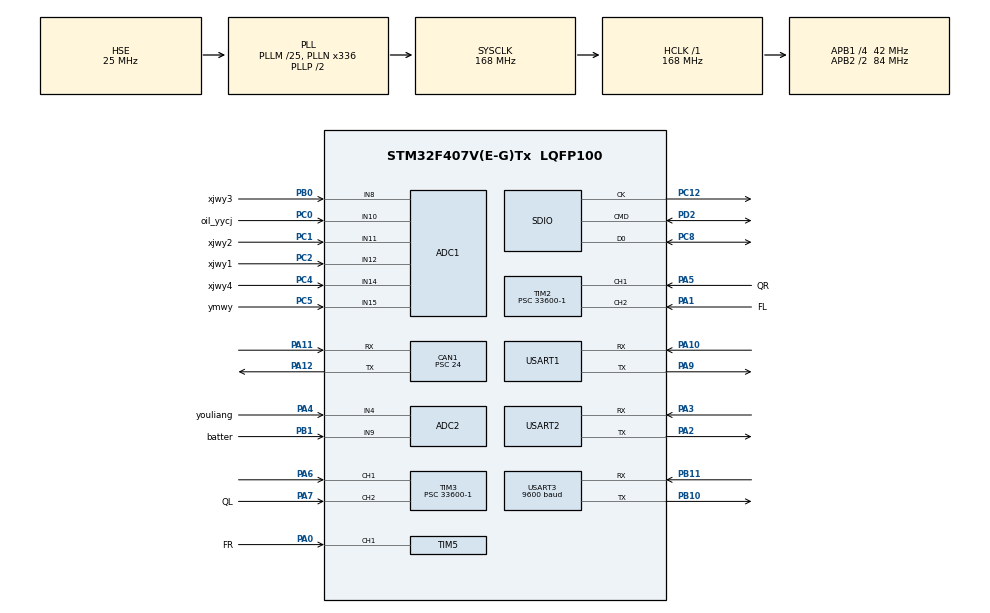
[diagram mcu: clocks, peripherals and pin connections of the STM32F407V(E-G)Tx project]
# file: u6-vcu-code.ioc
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ADC1.Channel-0\#ChannelRegularConversion=ADC_CHANNEL_12
ADC1.Channel-1\#ChannelRegularConversion=ADC_CHANNEL_11
ADC1.Channel-2\#ChannelRegularConversion=ADC_CHANNEL_8
ADC1.Channel-3\#ChannelRegularConversion=ADC_CHANNEL_14
ADC1.Channel-4\#ChannelRegularConversion=ADC_CHANNEL_10
ADC1.Channel-5\#ChannelRegularConversion=ADC_CHANNEL_15
ADC1.ContinuousConvMode=ENABLE
ADC1.DMAContinuousRequests=ENABLE
ADC1.DiscontinuousConvMode=DISABLE
ADC1.EOCSelection=ADC_EOC_SINGLE_CONV
ADC1.InjNumberOfConversion=0
ADC1.NbrOfConversion=6
ADC1.NbrOfConversionFlag=1
ADC1.Rank-0\#ChannelRegularConversion=1
ADC1.Rank-1\#ChannelRegularConversion=2
ADC1.Rank-2\#ChannelRegularConversion=3
ADC1.Rank-3\#ChannelRegularConversion=4
ADC1.Rank-4\#ChannelRegularConversion=5
ADC1.Rank-5\#ChannelRegularConversion=6
ADC1.SamplingTime-0\#ChannelRegularConversion=ADC_SAMPLETIME_480CYCLES
ADC1.SamplingTime-1\#ChannelRegularConversion=ADC_SAMPLETIME_480CYCLES
ADC1.SamplingTime-2\#ChannelRegularConversion=ADC_SAMPLETIME_480CYCLES
ADC1.SamplingTime-3\#ChannelRegularConversion=ADC_SAMPLETIME_480CYCLES
ADC1.SamplingTime-4\#ChannelRegularConversion=ADC_SAMPLETIME_480CYCLES
ADC1.SamplingTime-5\#ChannelRegularConversion=ADC_SAMPLETIME_480CYCLES
ADC1.ScanConvMode=ENABLE
ADC1.master=1
ADC2.Channel-0\#ChannelRegularConversion=ADC_CHANNEL_4
ADC2.Channel-1\#ChannelRegularConversion=ADC_CHANNEL_9
ADC2.ContinuousConvMode=ENABLE
ADC2.DMAContinuousRequests=ENABLE
ADC2.NbrOfConversion=2
ADC2.NbrOfConversionFlag=1
ADC2.Rank-0\#ChannelRegularConversion=1
ADC2.Rank-1\#ChannelRegularConversion=2
ADC2.SamplingTime-0\#ChannelRegularConversion=ADC_SAMPLETIME_480CYCLES
ADC2.SamplingTime-1\#ChannelRegularConversion=ADC_SAMPLETIME_480CYCLES
ADC2.ScanConvMode=ENABLE
CAN1.BS1=CAN_BS1_3TQ
CAN1.BS2=CAN_BS2_3TQ
CAN1.CalculateBaudRate=250000
CAN1.CalculateTimeBit=4000
CAN1.CalculateTimeQuantum=571.4285714285714
CAN1.Mode=CAN_MODE_NORMAL
CAN1.NART=DISABLE
CAN1.Prescaler=24
CAN1.TXFP=ENABLE
Dma.ADC1.5.Direction=DMA_PERIPH_TO_MEMORY
Dma.ADC1.5.FIFOMode=DMA_FIFOMODE_DISABLE
Dma.ADC1.5.Instance=DMA2_Stream0
Dma.ADC1.5.MemDataAlignment=DMA_MDATAALIGN_WORD
Dma.ADC1.5.MemInc=DMA_MINC_ENABLE
Dma.ADC1.5.Mode=DMA_CIRCULAR
Dma.ADC1.5.PeriphDataAlignment=DMA_PDATAALIGN_WORD
Dma.ADC1.5.PeriphInc=DMA_PINC_DISABLE
Dma.ADC1.5.Priority=DMA_PRIORITY_MEDIUM
Dma.ADC2.4.Direction=DMA_PERIPH_TO_MEMORY
Dma.ADC2.4.FIFOMode=DMA_FIFOMODE_ENABLE
Dma.ADC2.4.FIFOThreshold=DMA_FIFO_THRESHOLD_FULL
Dma.ADC2.4.Instance=DMA2_Stream2
Dma.ADC2.4.MemBurst=DMA_MBURST_SINGLE
Dma.ADC2.4.MemDataAlignment=DMA_MDATAALIGN_WORD
Dma.ADC2.4.MemInc=DMA_MINC_ENABLE
Dma.ADC2.4.Mode=DMA_CIRCULAR
Dma.ADC2.4.PeriphBurst=DMA_PBURST_SINGLE
Dma.ADC2.4.PeriphDataAlignment=DMA_PDATAALIGN_WORD
Dma.ADC2.4.PeriphInc=DMA_PINC_DISABLE
Dma.ADC2.4.Priority=DMA_PRIORITY_MEDIUM
Dma.Request0=SDIO_RX
Dma.Request1=SDIO_TX
Dma.Request2=USART1_TX
Dma.Request3=USART2_RX
Dma.Request4=ADC2
Dma.Request5=ADC1
Dma.SDIO_RX.0.Direction=DMA_PERIPH_TO_MEMORY
Dma.SDIO_RX.0.FIFOMode=DMA_FIFOMODE_ENABLE
Dma.SDIO_RX.0.FIFOThreshold=DMA_FIFO_THRESHOLD_FULL
Dma.SDIO_RX.0.Instance=DMA2_Stream3
Dma.SDIO_RX.0.MemBurst=DMA_MBURST_INC4
Dma.SDIO_RX.0.MemDataAlignment=DMA_MDATAALIGN_WORD
Dma.SDIO_RX.0.MemInc=DMA_MINC_ENABLE
Dma.SDIO_RX.0.Mode=DMA_PFCTRL
Dma.SDIO_RX.0.PeriphBurst=DMA_PBURST_INC4
Dma.SDIO_RX.0.PeriphDataAlignment=DMA_PDATAALIGN_WORD
Dma.SDIO_RX.0.PeriphInc=DMA_PINC_DISABLE
Dma.SDIO_RX.0.Priority=DMA_PRIORITY_MEDIUM
Dma.SDIO_TX.1.Direction=DMA_MEMORY_TO_PERIPH
Dma.SDIO_TX.1.FIFOMode=DMA_FIFOMODE_ENABLE
Dma.SDIO_TX.1.FIFOThreshold=DMA_FIFO_THRESHOLD_FULL
Dma.SDIO_TX.1.Instance=DMA2_Stream6
Dma.SDIO_TX.1.MemBurst=DMA_MBURST_INC4
Dma.SDIO_TX.1.MemDataAlignment=DMA_MDATAALIGN_WORD
Dma.SDIO_TX.1.MemInc=DMA_MINC_ENABLE
Dma.SDIO_TX.1.Mode=DMA_PFCTRL
Dma.SDIO_TX.1.PeriphBurst=DMA_PBURST_INC4
Dma.SDIO_TX.1.PeriphDataAlignment=DMA_PDATAALIGN_WORD
Dma.SDIO_TX.1.PeriphInc=DMA_PINC_DISABLE
Dma.SDIO_TX.1.Priority=DMA_PRIORITY_MEDIUM
Dma.USART1_TX.2.Direction=DMA_MEMORY_TO_PERIPH
Dma.USART1_TX.2.FIFOMode=DMA_FIFOMODE_DISABLE
Dma.USART1_TX.2.Instance=DMA2_Stream7
Dma.USART1_TX.2.MemDataAlignment=DMA_MDATAALIGN_BYTE
Dma.USART1_TX.2.MemInc=DMA_MINC_ENABLE
Dma.USART1_TX.2.Mode=DMA_NORMAL
Dma.USART1_TX.2.PeriphDataAlignment=DMA_PDATAALIGN_BYTE
Dma.USART1_TX.2.PeriphInc=DMA_PINC_DISABLE
Dma.USART1_TX.2.Priority=DMA_PRIORITY_LOW
Dma.USART2_RX.3.Direction=DMA_PERIPH_TO_MEMORY
Dma.USART2_RX.3.FIFOMode=DMA_FIFOMODE_DISABLE
Dma.USART2_RX.3.Instance=DMA1_Stream5
Dma.USART2_RX.3.MemDataAlignment=DMA_MDATAALIGN_BYTE
Dma.USART2_RX.3.MemInc=DMA_MINC_ENABLE
Dma.USART2_RX.3.Mode=DMA_NORMAL
Dma.USART2_RX.3.PeriphDataAlignment=DMA_PDATAALIGN_BYTE
Dma.USART2_RX.3.PeriphInc=DMA_PINC_DISABLE
Dma.USART2_RX.3.Priority=DMA_PRIORITY_VERY_HIGH
FATFS._CODE_PAGE=936
FATFS._MAX_SS=4096
FATFS._MIN_SS=512
FATFS._USE_LFN=2
FREERTOS.BinarySemaphores01=CanBinarySem,Static,CanBinarySemControlBlock;Onenet_tx_BinarySem,Static,Onenet_tx_BinarySemControlBlock;TyreBinarySem,Static,TypeBinarySemControlBlock
FREERTOS.Events01=Vcu_Event1,Static,Vcu_Event1ControlBlock;Can_Event,Static,Can_EventControlBlock;MT_Event,Static,MT_EventControlBlock;SD_Event,Static,SD_EventControlBlock
FREERTOS.Mutexes01=MqttMutex,Static,MqttMutexControlBlock
FREERTOS.Queues01=UsartQueue,4,64,1,Dynamic,NULL,NULL
FREERTOS.Tasks01=Wit_dat_Task,9,512,Wit_Dat_Handle,Default,NULL,Dynamic,NULL,NULL;Can_Rx_Task,10,128,Can_Rx_Handle,Default,NULL,Dynamic,NULL,NULL;RB_Read_Task,12,512,RingBuffer_Read_Handle,Default,NULL,Dynamic,NULL,NULL;OilDisplay_Task,13,512,OilDisplayment_Handle,Default,NULL,Dynamic,NULL,NULL;DTU_Init_Task,43,128,DTU_Init_Handle,Default,NULL,Dynamic,NULL,NULL;Signal_4G_Task,8,256,Signal_4G_Handle,Default,NULL,Dynamic,NULL,NULL;GPS_Init_Task,42,128,GPS_Init_Handle,Default,NULL,Dynamic,NULL,NULL;GPS_Get_Task,11,256,GPS_Get_Handle,Default,NULL,Dynamic,NULL,NULL;IWDG_Task,40,128,IWDG_Handle,Default,NULL,Dynamic,NULL,NULL;Otheradc_task,8,256,Oadc_Handle,Default,NULL,Dynamic,NULL,NULL;CantxTask,32,256,Cantx_Handle,Default,NULL,Static,CantxTaskBuffer,CantxTaskControlBlock;TyreSpeedTask,15,256,TyreSpeed_Handle,Default,NULL,Dynamic,NULL,NULL;SD_Init_task,41,128,SD_Init_Handle,Default,NULL,Dynamic,NULL,NULL;RTCTask,8,128,RTC_Handle,Default,NULL,Static,RTCTaskBuffer,RTCTaskControlBlock;CanrxTask,8,128,Canrx_Handle,Default,NULL,Dynamic,NULL,NULL
FREERTOS.configENABLE_FPU=1
FREERTOS.configLIBRARY_MAX_SYSCALL_INTERRUPT_PRIORITY=2
IWDG.Prescaler=IWDG_PRESCALER_32
IWDG.Reload=1000
Mcu.Family=STM32F4
Mcu.Name=STM32F407V(E-G)Tx
Mcu.Package=LQFP100
NVIC.ADC_IRQn=true\:2\:0\:false\:false\:true\:true\:true\:true\:true
NVIC.CAN1_RX0_IRQn=true\:2\:0\:false\:false\:true\:true\:true\:true\:true
NVIC.CAN1_TX_IRQn=true\:2\:0\:false\:false\:true\:true\:true\:true\:true
NVIC.DMA1_Stream5_IRQn=true\:2\:0\:false\:false\:true\:true\:false\:true\:true
NVIC.DMA2_Stream0_IRQn=true\:2\:0\:false\:false\:true\:true\:false\:true\:true
NVIC.DMA2_Stream2_IRQn=true\:2\:0\:false\:false\:true\:true\:false\:true\:true
NVIC.DMA2_Stream3_IRQn=true\:10\:0\:true\:false\:true\:true\:false\:true\:true
NVIC.DMA2_Stream6_IRQn=true\:10\:0\:true\:false\:true\:true\:false\:true\:true
NVIC.DMA2_Stream7_IRQn=true\:7\:0\:true\:false\:true\:true\:false\:true\:true
NVIC.FPU_IRQn=true\:2\:0\:true\:false\:true\:true\:true\:false\:true
NVIC.PriorityGroup=NVIC_PRIORITYGROUP_4
NVIC.SDIO_IRQn=true\:2\:0\:true\:false\:true\:true\:true\:true\:true
NVIC.TIM1_UP_TIM10_IRQn=true\:15\:0\:false\:false\:true\:false\:false\:true\:true
NVIC.TIM2_IRQn=true\:2\:0\:false\:false\:true\:true\:true\:true\:true
NVIC.TIM3_IRQn=true\:2\:0\:false\:false\:true\:true\:true\:true\:true
NVIC.TIM5_IRQn=true\:2\:0\:false\:false\:true\:true\:true\:true\:true
NVIC.TIM7_IRQn=true\:2\:0\:false\:false\:true\:true\:true\:true\:true
NVIC.TIM8_TRG_COM_TIM14_IRQn=true\:2\:0\:false\:false\:true\:true\:true\:true\:true
NVIC.TIM8_UP_TIM13_IRQn=true\:2\:0\:false\:false\:true\:true\:true\:true\:true
NVIC.TimeBase=TIM1_UP_TIM10_IRQn
NVIC.TimeBaseIP=TIM1
NVIC.USART2_IRQn=true\:5\:0\:true\:false\:true\:true\:true\:true\:true
NVIC.USART3_IRQn=true\:5\:0\:true\:false\:true\:true\:true\:true\:true
PA0-WKUP.GPIO_Label=FR
PA0-WKUP.Signal=S_TIM5_CH1
PA1.GPIO_Label=FL
PA1.Signal=S_TIM2_CH2
PA10.Mode=Asynchronous
PA10.Signal=USART1_RX
PA11.Mode=CAN_Activate
PA11.Signal=CAN1_RX
PA12.Mode=CAN_Activate
PA12.Signal=CAN1_TX
PA13.Mode=Serial_Wire
PA13.Signal=SYS_JTMS-SWDIO
PA14.Mode=Serial_Wire
PA14.Signal=SYS_JTCK-SWCLK
PA2.Mode=Asynchronous
PA2.Signal=USART2_TX
PA3.Mode=Asynchronous
PA3.Signal=USART2_RX
PA4.GPIO_Label=youliang
PA4.Signal=ADCx_IN4
PA5.GPIO_Label=QR
PA5.Signal=S_TIM2_CH1_ETR
PA6.Signal=S_TIM3_CH1
PA7.GPIO_Label=QL
PA7.Signal=S_TIM3_CH2
PA9.Mode=Asynchronous
PA9.Signal=USART1_TX
PB0.GPIO_Label=xjwy3
PB0.Signal=ADCx_IN8
PB1.GPIO_Label=batter
PB1.Signal=ADCx_IN9
PB10.Mode=Asynchronous
PB10.Signal=USART3_TX
PB11.Mode=Asynchronous
PB11.Signal=USART3_RX
PC0.GPIO_Label=oil_yycj
PC0.Signal=ADCx_IN10
PC1.GPIO_Label=xjwy2
PC1.Signal=ADCx_IN11
PC12.GPIO_PuPd=GPIO_PULLUP
PC12.Mode=SD_1_bit
PC12.Signal=SDIO_CK
PC2.GPIO_Label=xjwy1
PC2.Signal=ADCx_IN12
PC4.GPIO_Label=xjwy4
PC4.Signal=ADCx_IN14
PC5.GPIO_Label=ymwy
PC5.Signal=ADCx_IN15
PC8.GPIO_PuPd=GPIO_PULLUP
PC8.Mode=SD_1_bit
PC8.Signal=SDIO_D0
PD2.GPIO_PuPd=GPIO_PULLUP
PD2.Mode=SD_1_bit
PD2.Signal=SDIO_CMD
PH0-OSC_IN.Mode=HSE-External-Oscillator
PH0-OSC_IN.Signal=RCC_OSC_IN
PH1-OSC_OUT.Mode=HSE-External-Oscillator
PH1-OSC_OUT.Signal=RCC_OSC_OUT
ProjectManager.HeapSize=0x1000
ProjectManager.StackSize=0x1000
ProjectManager.TargetToolchain=MDK-ARM V5
RCC.48MHZClocksFreq_Value=48000000
RCC.AHBFreq_Value=168000000
RCC.APB1CLKDivider=RCC_HCLK_DIV4
RCC.APB1Freq_Value=42000000
RCC.APB1TimFreq_Value=84000000
RCC.APB2CLKDivider=RCC_HCLK_DIV2
RCC.APB2Freq_Value=84000000
RCC.APB2TimFreq_Value=168000000
RCC.CortexFreq_Value=168000000
RCC.HCLKFreq_Value=168000000
RCC.HSE_VALUE=25000000
RCC.HSI_VALUE=16000000
RCC.MCO1OutPutEnable-ClockTree=true
RCC.PLLI2SN=50
RCC.PLLM=25
RCC.PLLN=336
RCC.PLLQ=7
RCC.PLLSourceVirtual=RCC_PLLSOURCE_HSE
RCC.RCC_RTC_Clock_Source_FROM_HSE=RCC_RTCCLKSOURCE_HSE_DIV25
RCC.SYSCLKFreq_VALUE=168000000
RCC.SYSCLKSource=RCC_SYSCLKSOURCE_PLLCLK
RCC.USBHSEnable-ClockTree=true
RCC.VCOOutputFreq_Value=336000000
RTC.AsynchPrediv=4
RTC.Date=13
RTC.Hours=19
RTC.Month=RTC_MONTH_APRIL
RTC.WeekDay=RTC_WEEKDAY_SATURDAY
RTC.Year=24
SDIO.ClockDiv=0
SDIO.HardwareFlowControl=SDIO_HARDWARE_FLOW_CONTROL_DISABLE
SH.ADCx_IN10.0=ADC1_IN10,IN10
SH.ADCx_IN11.0=ADC1_IN11,IN11
SH.ADCx_IN12.0=ADC1_IN12,IN12
SH.ADCx_IN14.0=ADC1_IN14,IN14
SH.ADCx_IN15.0=ADC1_IN15,IN15
SH.ADCx_IN4.0=ADC2_IN4,IN4
SH.ADCx_IN8.0=ADC1_IN8,IN8
SH.ADCx_IN9.0=ADC2_IN9,IN9
SH.S_TIM2_CH1_ETR.0=TIM2_CH1,Input_Capture1_from_TI1
SH.S_TIM2_CH2.0=TIM2_CH2,Input_Capture2_from_TI2
SH.S_TIM3_CH1.0=TIM3_CH1,Input_Capture1_from_TI1
SH.S_TIM3_CH2.0=TIM3_CH2,Input_Capture2_from_TI2
SH.S_TIM5_CH1.0=TIM5_CH1,Input_Capture1_from_TI1
TIM13.Period=30000
TIM13.Prescaler=33600-1
TIM14.AutoReloadPreload=TIM_AUTORELOAD_PRELOAD_DISABLE
TIM14.Period=5-1
TIM14.Prescaler=33600-1
TIM2.AutoReloadPreload=TIM_AUTORELOAD_PRELOAD_ENABLE
TIM2.Channel-Input_Capture1_from_TI1=TIM_CHANNEL_1
TIM2.Channel-Input_Capture2_from_TI2=TIM_CHANNEL_2
TIM2.Prescaler=33600-1
TIM3.Channel-Input_Capture1_from_TI1=TIM_CHANNEL_1
TIM3.Channel-Input_Capture2_from_TI2=TIM_CHANNEL_2
TIM3.Period=50000
TIM3.Prescaler=33600-1
TIM5.Channel-Input_Capture1_from_TI1=TIM_CHANNEL_1
TIM5.Prescaler=33600-1
TIM7.Period=10-1
TIM7.Prescaler=16800-1
USART1.VirtualMode=VM_ASYNC
USART2.VirtualMode=VM_ASYNC
USART3.BaudRate=9600
USART3.VirtualMode=VM_ASYNC
VP_FATFS_VS_SDIO.Mode=SDIO
VP_FREERTOS_VS_CMSIS_V2.Mode=CMSIS_V2
VP_IWDG_VS_IWDG.Mode=IWDG_Activate
VP_RTC_VS_RTC_Activate.Mode=RTC_Enabled
VP_RTC_VS_RTC_Calendar.Mode=RTC_Calendar
VP_SYS_VS_tim1.Mode=TIM1
VP_TIM13_VS_ClockSourceINT.Mode=Enable_Timer
VP_TIM14_VS_ClockSourceINT.Mode=Enable_Timer
VP_TIM2_VS_ClockSourceINT.Mode=Internal
VP_TIM3_VS_ClockSourceINT.Mode=Internal
VP_TIM5_VS_ClockSourceINT.Mode=Internal
VP_TIM7_VS_ClockSourceINT.Mode=Enable_Timer
board=custom

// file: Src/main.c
/* USER CODE BEGIN Header */
/**
  ******************************************************************************
  * @file           : main.c
  * @brief          : Main program body
  ******************************************************************************
  * @attention
  *
  * Copyright (c) 2023 STMicroelectronics.
  * All rights reserved.
  *
  * This software is licensed under terms that can be found in the LICENSE file
  * in the root directory of this software component.
  * If no LICENSE file comes with this software, it is provided AS-IS.
  *
  ******************************************************************************
  */
/* USER CODE END Header */
#include "main.h"
#include "cmsis_os.h"
#include "adc.h"
#include "can.h"
#include "dma.h"
#include "fatfs.h"
#include "iwdg.h"
#include "rtc.h"
#include "sdio.h"
#include "tim.h"
#include "usart.h"
#include "gpio.h"

/* USER CODE BEGIN Includes */
#include "wit_c_sdk.h"
#include "atk_m750.h"
#include "RingBuffer.h"
#include "string.h"
#include "gps.h"
#include "mtspeed.h"
/* USER CODE END Includes */

/* USER CODE BEGIN PTD */
/*******************************************
	*文件名 ：  U6_VCU
	*作   者：  罗成
	*修改时间： 2024.4.18
	*版   本：  v5.1.6
	*声   明：  本程序归飞翼车队所有，未经车队队长及指导老师允许，不能对外传播
	*提   示：  本程序采用Git进行版本管理，可通过git退回以前版本，但在选择时请选择
							最高版本（随版本递增，功能逐步递增）
							github仓库：https://github.com/TheorangeMr/U6xxxx.git
*******************************************/
/* USER CODE END PTD */

/* USER CODE BEGIN PV */

extern uint8_t Oil_base_dat;
extern mt_rotate mtspeed1;
extern mt_rotate mtspeed2;
extern mt_rotate mtspeed3;
extern mt_rotate mtspeed4;
extern mt_rotate mtspeed5;
extern __IO uint16_t USART3_RX_STA;

uint8_t cantx_dat[8] = {0};
uint8_t time3_over1 = 0,time3_over2 = 0;

/* USER CODE END PV */

void SystemClock_Config(void);
void MX_FREERTOS_Init(void);

/* USER CODE BEGIN 0 */

/*
	函数名：Wit_Can_Send_Msg()
	功  能：CAN发送帧函数
  参  数：u8 ucStdId：扩展标识符, u8* msg：数据指针, u8 len：数据长度
  返回值：PASSED:传输成功，FAILED:失败
*/

void Wit_Can_Send_Msg(uint8_t ucStdId, uint8_t* msg, uint32_t len)
{
	uint16_t i=0;uint32_t can_tx_mailbox = 0;
	uint8_t canovertime = 0;
	CAN_TxHeaderTypeDef TxMessage;
	TxMessage.StdId=ucStdId;
	TxMessage.ExtId=0;
	TxMessage.IDE=CAN_ID_STD;
	TxMessage.RTR=CAN_RTR_DATA;
	TxMessage.DLC=len;
	TxMessage.TransmitGlobalTime=DISABLE;
	for(i=0;i<len;i++)
	cantx_dat[i]=msg[i];
	while(HAL_CAN_GetTxMailboxesFreeLevel(&hcan1) < 1){
		if(canovertime++ >= 5){
			break;
		}else{
			osDelay(1);
		}
	}
	if(HAL_CAN_AddTxMessage(&hcan1,&TxMessage,cantx_dat,&can_tx_mailbox) != HAL_OK)
	{
		printf ("data sending failure！\r\n");
	}
}

/* USER CODE END 0 */

int main(void)
{

  /* MCU Configuration--------------------------------------------------------*/

  /* Reset of all peripherals, Initializes the Flash interface and the Systick. */
  HAL_Init();

  /* Configure the system clock */
  SystemClock_Config();

  /* Initialize all configured peripherals */
  MX_GPIO_Init();
  MX_DMA_Init();
  MX_CAN1_Init();
  MX_SDIO_SD_Init();
  MX_FATFS_Init();
  MX_USART1_UART_Init();
  MX_USART2_UART_Init();
  MX_USART3_UART_Init();
  MX_ADC1_Init();
  MX_TIM2_Init();
  MX_TIM14_Init();
  MX_IWDG_Init();
  MX_ADC2_Init();
  MX_TIM3_Init();
  MX_TIM5_Init();
  MX_TIM7_Init();
  MX_TIM13_Init();
  MX_RTC_Init();
  /* USER CODE BEGIN 2 */

	//nine-axis dvice initialize
	WitInit(WIT_PROTOCOL_CAN, 0x50);
	WitRegisterCallBack(SensorDataUpdata);
	WitCanWriteRegister(Wit_Can_Send_Msg);
	WitDelayMsRegister(Wit_Delayms);

	HAL_GPIO_WritePin(GPIOB,GPIO_PIN_3,GPIO_PIN_RESET);
	HAL_GPIO_WritePin(GPIOA,GPIO_PIN_15,GPIO_PIN_RESET);

	BSP_SD_Init();
  printf("外设初始化\r\n");
  /* USER CODE END 2 */

  /* Init scheduler */
  osKernelInitialize();  /* Call init function for freertos objects (in freertos.c) */
  MX_FREERTOS_Init();

  /* Start scheduler */
  osKernelStart();
  /* We should never get here as control is now taken by the scheduler */
  /* Infinite loop */
  while (1)
  {

  }
}

void SystemClock_Config(void)
{
  RCC_OscInitTypeDef RCC_OscInitStruct = {0};
  RCC_ClkInitTypeDef RCC_ClkInitStruct = {0};

  /** Configure the main internal regulator output voltage
  */
  __HAL_RCC_PWR_CLK_ENABLE();
  __HAL_PWR_VOLTAGESCALING_CONFIG(PWR_REGULATOR_VOLTAGE_SCALE1);

  /** Initializes the RCC Oscillators according to the specified parameters
  * in the RCC_OscInitTypeDef structure.
  */
  RCC_OscInitStruct.OscillatorType = RCC_OSCILLATORTYPE_LSI|RCC_OSCILLATORTYPE_HSE;
  RCC_OscInitStruct.HSEState = RCC_HSE_ON;
  RCC_OscInitStruct.LSIState = RCC_LSI_ON;
  RCC_OscInitStruct.PLL.PLLState = RCC_PLL_ON;
  RCC_OscInitStruct.PLL.PLLSource = RCC_PLLSOURCE_HSE;
  RCC_OscInitStruct.PLL.PLLM = 25;
  RCC_OscInitStruct.PLL.PLLN = 336;
  RCC_OscInitStruct.PLL.PLLP = RCC_PLLP_DIV2;
  RCC_OscInitStruct.PLL.PLLQ = 7;
  if (HAL_RCC_OscConfig(&RCC_OscInitStruct) != HAL_OK)
  {
    Error_Handler();
  }

  /** Initializes the CPU, AHB and APB buses clocks
  */
  RCC_ClkInitStruct.ClockType = RCC_CLOCKTYPE_HCLK|RCC_CLOCKTYPE_SYSCLK
                              |RCC_CLOCKTYPE_PCLK1|RCC_CLOCKTYPE_PCLK2;
  RCC_ClkInitStruct.SYSCLKSource = RCC_SYSCLKSOURCE_PLLCLK;
  RCC_ClkInitStruct.AHBCLKDivider = RCC_SYSCLK_DIV1;
  RCC_ClkInitStruct.APB1CLKDivider = RCC_HCLK_DIV4;
  RCC_ClkInitStruct.APB2CLKDivider = RCC_HCLK_DIV2;

  if (HAL_RCC_ClockConfig(&RCC_ClkInitStruct, FLASH_LATENCY_5) != HAL_OK)
  {
    Error_Handler();
  }
}

void HAL_TIM_PeriodElapsedCallback(TIM_HandleTypeDef *htim)
{
  /* USER CODE BEGIN Callback 0 */
	#define mt_cycle   300                     //mt算法采样周期
	#define reset_cycle   800                  //当不采样时的清零周期

	static uint8_t tim14_count = 0;
  /* USER CODE END Callback 0 */
  if (htim->Instance == TIM1) {
    HAL_IncTick();
  }
  /* USER CODE BEGIN Callback 1 */

  if (htim->Instance == TIM14) {
		if(mtspeed1.timecountflag){
			mtspeed1.timecount++;
			if(mtspeed1.timecount >= mt_cycle){
				mtspeed1.timecount = 0;
				mtspeed1.timecountflag = 0;
				mtspeed1.Endup_Flag = 1;                                           //规定周期采样结束标志
			}
		}else{
			mtspeed1.speed_zero++;
			if(mtspeed1.speed_zero >= reset_cycle){
				mtspeed1.Rotate_Speed = 0;
			}
		}
		if(mtspeed2.timecountflag){
			mtspeed2.timecount++;
			if(mtspeed2.timecount >= mt_cycle){
				mtspeed2.timecountflag = 0;
				mtspeed2.timecount = 0;
				mtspeed2.Endup_Flag = 1;                                           //规定周期采样结束标志
			}
		}else{
			mtspeed2.speed_zero++;
			if(mtspeed2.speed_zero >= reset_cycle){
				mtspeed2.Rotate_Speed = 0;
			}
		}
		if(mtspeed3.timecountflag){
			mtspeed3.timecount++;
			if(mtspeed3.timecount >= mt_cycle){
				mtspeed3.timecountflag = 0;
				mtspeed3.timecount = 0;
				mtspeed3.Endup_Flag = 1;                                           //规定周期采样结束标志
			}
		}else{
			mtspeed3.speed_zero++;
			if(mtspeed3.speed_zero >= reset_cycle){
				mtspeed3.Rotate_Speed = 0;
			}
		}
		if(mtspeed4.timecountflag){
			mtspeed4.timecount++;
			if(mtspeed4.timecount >= mt_cycle){
				mtspeed4.timecountflag = 0;
				mtspeed4.timecount = 0;
				mtspeed4.Endup_Flag = 1;                                           //规定周期采样结束标志
			}
		}else{
			mtspeed4.speed_zero++;
			if(mtspeed4.speed_zero >= reset_cycle){
				mtspeed4.Rotate_Speed = 0;
			}
		}
		if(mtspeed5.timecountflag){
			mtspeed5.timecount++;
			if(mtspeed5.timecount >= mt_cycle){
				mtspeed5.timecountflag = 0;
				mtspeed5.timecount = 0;
				mtspeed5.Endup_Flag = 1;                                           //规定周期采样结束标志
			}
		}else{
			mtspeed5.speed_zero++;
			if(mtspeed5.speed_zero >= reset_cycle){
				mtspeed5.Rotate_Speed = 0;
			}
		}
	}
	if(htim->Instance == TIM3){
//		printf("timer3 timeout!!!\r\n");
		//time3计数器计数溢出，本次测速丢弃
		time3_over1 = 1;
		time3_over2 = 1;
	}
	if(htim->Instance == TIM7){
//		printf("timer7 timeout!!!\r\n");
		USART3_RX_STA|=1<<15;	//标记接收完成
		__HAL_TIM_DISABLE(&htim7);
	}
	if (htim->Instance == TIM13){
		tim14_count++;
		if(tim14_count >= 10)
		{
			if(Oil_base_dat > 0)
			{
				Oil_base_dat--;
			}
      tim14_count = 0;
		}
  }
  /* USER CODE END Callback 1 */
}

void Error_Handler(void)
{
  /* USER CODE BEGIN Error_Handler_Debug */
  /* User can add his own implementation to report the HAL error return state */
  __disable_irq();
	printf("Error_Handler\r\n");
  while (1)
  {
  }
  /* USER CODE END Error_Handler_Debug */
}

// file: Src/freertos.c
/* USER CODE BEGIN Header */
/**
  ******************************************************************************
  * File Name          : freertos.c
  * Description        : Code for freertos applications
  ******************************************************************************
  * @attention
  *
  * Copyright (c) 2023 STMicroelectronics.
  * All rights reserved.
  *
  * This software is licensed under terms that can be found in the LICENSE file
  * in the root directory of this software component.
  * If no LICENSE file comes with this software, it is provided AS-IS.
  *
  ******************************************************************************
  */
/* USER CODE END Header */

#include "FreeRTOS.h"
#include "task.h"
#include "main.h"
#include "cmsis_os.h"

/* USER CODE BEGIN Includes */
#include "atk_m750.h"
#include "RingBuffer.h"
#include "wit_c_sdk.h"
#include "stdlib.h"
#include "gps.h"
#include "usart.h"
#include "mtspeed.h"
#include "fatfs.h"
#include "iwdg.h"
#include "adc.h"
#include "can.h"
#include "tim.h"
#include "sdio.h"
#include "rtc.h"

/* USER CODE END Includes */

typedef StaticTask_t osStaticThreadDef_t;
typedef StaticSemaphore_t osStaticMutexDef_t;
typedef StaticSemaphore_t osStaticSemaphoreDef_t;
typedef StaticEventGroup_t osStaticEventGroupDef_t;

/* USER CODE BEGIN PD */

#define Q_TOOTH_NUM 24			 //齿数
#define F_TOOTH_NUM 48			 //齿数
#define J_TOOTH_NUM 50			 //减速器齿数
#define WHEEL_RADIUS 0.257 //轮径(单位:m)
#define PI 3.14						 //圆周率
#define TANK_HEIGHT 210		 //油箱高度
#define GEAR_RATIO  3.45    //传动比

#define XJWY_StdId							0x01
#define GPS_StdId								0x02
#define CLK_StdId								0x03
#define CLK_StdId2								0x13
#define DTU_StdId								0x04       //0x04     csq
#define OADC_StdId              0x05
#define Tyre_StdId              0x08
#define Wit_StdId_xy   						0x51      //0x51,0x52  angle_value-xy,z
#define Wit_dat   							((uint32_t)0x50) //标识符ID：0x50    (标准帧)

#define Wit_Device_ID        ((uint8_t)0x01)
#define XJ_Device_ID        ((uint8_t)0x02)             //油门踏板
#define GPS_Device_ID        ((uint8_t)0x03)
#define DTU_Device_ID        ((uint8_t)0x04)
#define TYRE_Device_ID       ((uint8_t)0x05)

/*
*************************************************************************
*               thread interval allocation
*************************************************************************
*/
#define   Wit_Dat_Handle_Delay          30
#define   Type_Dat_Handle_Delay         200
#define   Can_Rx_Handle_Delay           1
#define   GPS_Handle_Delay              100
#define   OD_Handle_Delay               100
#define   ADC_Handle_Delay              20000
#define   DTU_Signal_Delay              30000
#define   RTC_Delay                     900

/*
*************************************************************************
*                event flag
*************************************************************************
*/

#define EVENTBIT_0	(1<<0)				//九轴事件
#define EVENTBIT_1	(1<<1)				//接受4g反馈信息事件
#define EVENTBIT_2	(1<<2)				//4g信号事件

#define EVENTBIT_3	(1<<3)				//判断是否处于控制阶段 0处于配置状态 1处于透传状态
#define EVENTBIT_4	(1<<4)

#define EVENTBIT_5	(1<<5)				//暂未使用
#define EVENTBIT_6	(1<<6)        //暂未使用
#define EVENTBIT_7	(1<<7)				//暂未使用

#define EVENTBIT_8	(1<<8)				// GPS数据采集时间
#define EVENTBIT_9	(1<<9)				//暂未使用
#define EVENTBIT_10 (1<<10)       //暂未使用

#define MT_EVENTBIT_1	(1<<0)
#define MT_EVENTBIT_2	(1<<1)
#define MT_EVENTBIT_3	(1<<2)
#define MT_EVENTBIT_4	(1<<3)
#define MT_EVENTBIT_5	(1<<4)

#define SD_EVENTBIT_1	(1<<0)			//sd卡悬架位移事件
#define SD_EVENTBIT_2	(1<<1)			//sd九轴数据事件
#define SD_EVENTBIT_3	(1<<2)		  //sd轮速数据事件
#define SD_EVENTBIT_4	(1<<3)			//gps速度事件

#define CAN_EVENTBIT_1	(1<<0)
#define CAN_EVENTBIT_2	(1<<1)
#define CAN_EVENTBIT_3	(1<<2)
#define CAN_EVENTBIT_4	(1<<3)
#define CAN_EVENTBIT_5	(1<<4)
#define CAN_EVENTBIT_6	(1<<5)
#define CAN_EVENTBIT_7	(1<<6)
#define CAN_EVENTBIT_8	(1<<7)

/* USER CODE END PD */

/* USER CODE BEGIN Variables */

extern uint8_t USART3_RX_BUF[USART3_MAX_RECV_LEN]; 				//接收缓冲,最大USART3_MAX_RECV_LEN个字节.
extern uint8_t  USART3_TX_BUF[USART3_MAX_SEND_LEN]; 			//发送缓冲,最大USART3_MAX_SEND_LEN字节
uint8_t USART1_TX_BUF[USART3_MAX_RECV_LEN]; 					//串口1,发送缓存区

__IO uint16_t USART3_RX_STA=0;
extern uint8_t rx_4g_buffer[128];
extern uint8_t rx_len;
extern uint8_t rx_flag;
extern uint8_t usart_rx_char;
//adc
__IO uint8_t ADC1_Flag = 0;
__IO uint8_t ADC2_Flag = 0;
extern  uint32_t adc1_value[60];

//九轴传感器
extern RegUpdateCb p_WitRegUpdateCbFunc;
extern volatile char  s_cDataUpdate;
wit_can_dat wit_dat1 = {{0,0,0},{0,0,0},{0,0,0}};

union Anglefloat
{
	float value;
	uint8_t data[4];
}Anglefloat_tx[3];

union Accfloat
{
	float value;
	uint8_t data[4];
}Accfloat_tx[3];

//can

CAN_RxHeaderTypeDef RxMessage;
uint8_t canrx_dat[8] = {0};
uint8_t wit_msg[3][8] = {0};
uint8_t xjwy_msg[7] = {0};
uint8_t Clkvalue[6] = {0};
uint8_t oadc_msg[2] = {0};
uint8_t tyre_msg[8] = {0};

//onenet
extern const char sqpa[4][4];
const char ONENET_COM_OFF[]="lc0218";
const char ONENET_COM_ON[] = "lc2001";
RingBuffer *p_uart2_rxbuf;
_dtu_4g_device dtu_device1 = {0,0,0,{0},1,0};

//Tyre_speed

extern uint8_t time3_over1,time3_over2;

mt_rotate mtspeed1 = {0,0,0,0,0,0,0,0,0,0};
mt_rotate mtspeed2 = {0,0,0,0,0,0,0,0,0,0};
mt_rotate mtspeed3 = {0,0,0,0,0,0,0,0,0,0};
mt_rotate mtspeed4 = {0,0,0,0,0,0,0,0,0,0};
mt_rotate mtspeed5 = {0,0,0,0,0,0,0,0,0,0};

//位移传感器结构体

typedef struct
{
	uint8_t displacement_dat;
	uint8_t xjwy1_dat;
	uint8_t xjwy2_dat;
	uint8_t xjwy3_dat;
	uint8_t xjwy4_dat;
	uint8_t oilyy_dat[2];
}_wy_dat;

_wy_dat Wy_dat = {0,0,0,0,0,0};

//GPS

union speed_float
{
	float value;
	uint8_t data[4];
}speedfloat_tx;

uint8_t UpdateTime_flag = 0;

nmea_msg gpsx; 											//GPS信息
const uint8_t *fixmode_tbl[4]={"Fail","Fail"," 2D "," 3D "};	//fix mode字符串

//SD
extern FATFS SDFatFS;    /* File system object for SD logical drive */
extern FIL SDFile;       /* File object for SD */
HAL_SD_CardInfoTypeDef  SDCardInfo;

//oil
extern uint32_t adc2_value[20];
__IO uint8_t Oil_base_dat = 97;                     //油量最终基准值

//RTC

RTC_TimeTypeDef rtcTime;
RTC_DateTypeDef GetData;   //获取日期结构
uint8_t RTC_Start_flag = 0;

//uwtick
uint32_t uwtin[10] = {0};

/* USER CODE END Variables */
/* Definitions for Wit_dat_Task */
osThreadId_t Wit_dat_TaskHandle;
const osThreadAttr_t Wit_dat_Task_attributes = {
  .name = "Wit_dat_Task",
  .stack_size = 512 * 4,
  .priority = (osPriority_t) osPriorityLow1,
};
/* Definitions for Can_Rx_Task */
osThreadId_t Can_Rx_TaskHandle;
const osThreadAttr_t Can_Rx_Task_attributes = {
  .name = "Can_Rx_Task",
  .stack_size = 128 * 4,
  .priority = (osPriority_t) osPriorityLow2,
};
/* Definitions for RB_Read_Task */
osThreadId_t RB_Read_TaskHandle;
const osThreadAttr_t RB_Read_Task_attributes = {
  .name = "RB_Read_Task",
  .stack_size = 512 * 4,
  .priority = (osPriority_t) osPriorityLow4,
};
/* Definitions for OilDisplay_Task */
osThreadId_t OilDisplay_TaskHandle;
const osThreadAttr_t OilDisplay_Task_attributes = {
  .name = "OilDisplay_Task",
  .stack_size = 512 * 4,
  .priority = (osPriority_t) osPriorityLow5,
};
/* Definitions for DTU_Init_Task */
osThreadId_t DTU_Init_TaskHandle;
const osThreadAttr_t DTU_Init_Task_attributes = {
  .name = "DTU_Init_Task",
  .stack_size = 128 * 4,
  .priority = (osPriority_t) osPriorityHigh3,
};
/* Definitions for Signal_4G_Task */
osThreadId_t Signal_4G_TaskHandle;
const osThreadAttr_t Signal_4G_Task_attributes = {
  .name = "Signal_4G_Task",
  .stack_size = 256 * 4,
  .priority = (osPriority_t) osPriorityLow,
};
/* Definitions for GPS_Init_Task */
osThreadId_t GPS_Init_TaskHandle;
const osThreadAttr_t GPS_Init_Task_attributes = {
  .name = "GPS_Init_Task",
  .stack_size = 128 * 4,
  .priority = (osPriority_t) osPriorityHigh2,
};
/* Definitions for GPS_Get_Task */
osThreadId_t GPS_Get_TaskHandle;
const osThreadAttr_t GPS_Get_Task_attributes = {
  .name = "GPS_Get_Task",
  .stack_size = 256 * 4,
  .priority = (osPriority_t) osPriorityLow3,
};
/* Definitions for IWDG_Task */
osThreadId_t IWDG_TaskHandle;
const osThreadAttr_t IWDG_Task_attributes = {
  .name = "IWDG_Task",
  .stack_size = 128 * 4,
  .priority = (osPriority_t) osPriorityHigh,
};
/* Definitions for Otheradc_task */
osThreadId_t Otheradc_taskHandle;
const osThreadAttr_t Otheradc_task_attributes = {
  .name = "Otheradc_task",
  .stack_size = 256 * 4,
  .priority = (osPriority_t) osPriorityLow,
};
/* Definitions for CantxTask */
osThreadId_t CantxTaskHandle;
uint32_t CantxTaskBuffer[ 256 ];
osStaticThreadDef_t CantxTaskControlBlock;
const osThreadAttr_t CantxTask_attributes = {
  .name = "CantxTask",
  .cb_mem = &CantxTaskControlBlock,
  .cb_size = sizeof(CantxTaskControlBlock),
  .stack_mem = &CantxTaskBuffer[0],
  .stack_size = sizeof(CantxTaskBuffer),
  .priority = (osPriority_t) osPriorityAboveNormal,
};
/* Definitions for TyreSpeedTask */
osThreadId_t TyreSpeedTaskHandle;
const osThreadAttr_t TyreSpeedTask_attributes = {
  .name = "TyreSpeedTask",
  .stack_size = 256 * 4,
  .priority = (osPriority_t) osPriorityLow7,
};
/* Definitions for SD_Init_task */
osThreadId_t SD_Init_taskHandle;
const osThreadAttr_t SD_Init_task_attributes = {
  .name = "SD_Init_task",
  .stack_size = 128 * 4,
  .priority = (osPriority_t) osPriorityHigh1,
};
/* Definitions for RTCTask */
osThreadId_t RTCTaskHandle;
uint32_t RTCTaskBuffer[ 128 ];
osStaticThreadDef_t RTCTaskControlBlock;
const osThreadAttr_t RTCTask_attributes = {
  .name = "RTCTask",
  .cb_mem = &RTCTaskControlBlock,
  .cb_size = sizeof(RTCTaskControlBlock),
  .stack_mem = &RTCTaskBuffer[0],
  .stack_size = sizeof(RTCTaskBuffer),
  .priority = (osPriority_t) osPriorityLow,
};
/* Definitions for CanrxTask */
osThreadId_t CanrxTaskHandle;
const osThreadAttr_t CanrxTask_attributes = {
  .name = "CanrxTask",
  .stack_size = 128 * 4,
  .priority = (osPriority_t) osPriorityLow,
};
/* Definitions for UsartQueue */
osMessageQueueId_t UsartQueueHandle;
const osMessageQueueAttr_t UsartQueue_attributes = {
  .name = "UsartQueue"
};
/* Definitions for MqttMutex */
osMutexId_t MqttMutexHandle;
osStaticMutexDef_t MqttMutexControlBlock;
const osMutexAttr_t MqttMutex_attributes = {
  .name = "MqttMutex",
  .cb_mem = &MqttMutexControlBlock,
  .cb_size = sizeof(MqttMutexControlBlock),
};
/* Definitions for CanBinarySem */
osSemaphoreId_t CanBinarySemHandle;
osStaticSemaphoreDef_t CanBinarySemControlBlock;
const osSemaphoreAttr_t CanBinarySem_attributes = {
  .name = "CanBinarySem",
  .cb_mem = &CanBinarySemControlBlock,
  .cb_size = sizeof(CanBinarySemControlBlock),
};
/* Definitions for Onenet_tx_BinarySem */
osSemaphoreId_t Onenet_tx_BinarySemHandle;
osStaticSemaphoreDef_t Onenet_tx_BinarySemControlBlock;
const osSemaphoreAttr_t Onenet_tx_BinarySem_attributes = {
  .name = "Onenet_tx_BinarySem",
  .cb_mem = &Onenet_tx_BinarySemControlBlock,
  .cb_size = sizeof(Onenet_tx_BinarySemControlBlock),
};
/* Definitions for TyreBinarySem */
osSemaphoreId_t TyreBinarySemHandle;
osStaticSemaphoreDef_t TypeBinarySemControlBlock;
const osSemaphoreAttr_t TyreBinarySem_attributes = {
  .name = "TyreBinarySem",
  .cb_mem = &TypeBinarySemControlBlock,
  .cb_size = sizeof(TypeBinarySemControlBlock),
};
/* Definitions for Vcu_Event1 */
osEventFlagsId_t Vcu_Event1Handle;
osStaticEventGroupDef_t Vcu_Event1ControlBlock;
const osEventFlagsAttr_t Vcu_Event1_attributes = {
  .name = "Vcu_Event1",
  .cb_mem = &Vcu_Event1ControlBlock,
  .cb_size = sizeof(Vcu_Event1ControlBlock),
};
/* Definitions for Can_Event */
osEventFlagsId_t Can_EventHandle;
osStaticEventGroupDef_t Can_EventControlBlock;
const osEventFlagsAttr_t Can_Event_attributes = {
  .name = "Can_Event",
  .cb_mem = &Can_EventControlBlock,
  .cb_size = sizeof(Can_EventControlBlock),
};
/* Definitions for MT_Event */
osEventFlagsId_t MT_EventHandle;
osStaticEventGroupDef_t MT_EventControlBlock;
const osEventFlagsAttr_t MT_Event_attributes = {
  .name = "MT_Event",
  .cb_mem = &MT_EventControlBlock,
  .cb_size = sizeof(MT_EventControlBlock),
};
/* Definitions for SD_Event */
osEventFlagsId_t SD_EventHandle;
osStaticEventGroupDef_t SD_EventControlBlock;
const osEventFlagsAttr_t SD_Event_attributes = {
  .name = "SD_Event",
  .cb_mem = &SD_EventControlBlock,
  .cb_size = sizeof(SD_EventControlBlock),
};

void Wit_Dat_Handle(void *argument);
void Can_Rx_Handle(void *argument);
void RingBuffer_Read_Handle(void *argument);
void OilDisplayment_Handle(void *argument);
void DTU_Init_Handle(void *argument);
void Signal_4G_Handle(void *argument);
void GPS_Init_Handle(void *argument);
void GPS_Get_Handle(void *argument);
void IWDG_Handle(void *argument);
void Oadc_Handle(void *argument);
void Cantx_Handle(void *argument);
void TyreSpeed_Handle(void *argument);
void SD_Init_Handle(void *argument);
void RTC_Handle(void *argument);
void Canrx_Handle(void *argument);
void MX_FREERTOS_Init(void); /* (MISRA C 2004 rule 8.1) */

void MX_FREERTOS_Init(void) {
  /* Create the mutex(es) */
  /* creation of MqttMutex */
  MqttMutexHandle = osMutexNew(&MqttMutex_attributes);

  /* Create the semaphores(s) */
  /* creation of CanBinarySem */
  CanBinarySemHandle = osSemaphoreNew(1, 1, &CanBinarySem_attributes);

  /* creation of Onenet_tx_BinarySem */
  Onenet_tx_BinarySemHandle = osSemaphoreNew(1, 1, &Onenet_tx_BinarySem_attributes);

  /* creation of TyreBinarySem */
  TyreBinarySemHandle = osSemaphoreNew(1, 1, &TyreBinarySem_attributes);

  /* Create the queue(s) */
  /* creation of UsartQueue */
  UsartQueueHandle = osMessageQueueNew (4, 64, &UsartQueue_attributes);

  /* Create the thread(s) */
  /* creation of Wit_dat_Task */
  Wit_dat_TaskHandle = osThreadNew(Wit_Dat_Handle, NULL, &Wit_dat_Task_attributes);

  /* creation of Can_Rx_Task */
  Can_Rx_TaskHandle = osThreadNew(Can_Rx_Handle, NULL, &Can_Rx_Task_attributes);

  /* creation of RB_Read_Task */
  RB_Read_TaskHandle = osThreadNew(RingBuffer_Read_Handle, NULL, &RB_Read_Task_attributes);

  /* creation of OilDisplay_Task */
  OilDisplay_TaskHandle = osThreadNew(OilDisplayment_Handle, NULL, &OilDisplay_Task_attributes);

  /* creation of DTU_Init_Task */
  DTU_Init_TaskHandle = osThreadNew(DTU_Init_Handle, NULL, &DTU_Init_Task_attributes);

  /* creation of Signal_4G_Task */
  Signal_4G_TaskHandle = osThreadNew(Signal_4G_Handle, NULL, &Signal_4G_Task_attributes);

  /* creation of GPS_Init_Task */
  GPS_Init_TaskHandle = osThreadNew(GPS_Init_Handle, NULL, &GPS_Init_Task_attributes);

  /* creation of GPS_Get_Task */
  GPS_Get_TaskHandle = osThreadNew(GPS_Get_Handle, NULL, &GPS_Get_Task_attributes);

  /* creation of IWDG_Task */
  IWDG_TaskHandle = osThreadNew(IWDG_Handle, NULL, &IWDG_Task_attributes);

  /* creation of Otheradc_task */
  Otheradc_taskHandle = osThreadNew(Oadc_Handle, NULL, &Otheradc_task_attributes);

  /* creation of CantxTask */
  CantxTaskHandle = osThreadNew(Cantx_Handle, NULL, &CantxTask_attributes);

  /* creation of TyreSpeedTask */
  TyreSpeedTaskHandle = osThreadNew(TyreSpeed_Handle, NULL, &TyreSpeedTask_attributes);

  /* creation of SD_Init_task */
  SD_Init_taskHandle = osThreadNew(SD_Init_Handle, NULL, &SD_Init_task_attributes);

  /* creation of RTCTask */
  RTCTaskHandle = osThreadNew(RTC_Handle, NULL, &RTCTask_attributes);

  /* creation of CanrxTask */
  CanrxTaskHandle = osThreadNew(Canrx_Handle, NULL, &CanrxTask_attributes);

  /* USER CODE BEGIN RTOS_THREADS */
  /* add threads, ... */

	osSemaphoreAcquire(Onenet_tx_BinarySemHandle,osWaitForever);
	osSemaphoreAcquire(CanBinarySemHandle,osWaitForever);

  /* USER CODE END RTOS_THREADS */

  /* creation of Vcu_Event1 */
  Vcu_Event1Handle = osEventFlagsNew(&Vcu_Event1_attributes);

  /* creation of Can_Event */
  Can_EventHandle = osEventFlagsNew(&Can_Event_attributes);

  /* creation of MT_Event */
  MT_EventHandle = osEventFlagsNew(&MT_Event_attributes);

  /* creation of SD_Event */
  SD_EventHandle = osEventFlagsNew(&SD_Event_attributes);

  /* USER CODE BEGIN RTOS_EVENTS */
  /* add events, ... */
	Bsp_Start_IT();
	for(uint8_t i = 0;i<10;i++){
		uwtin[i] = uwTick;
	}
	if(NULL != DTU_Init_TaskHandle)/* 创建成功 */
		printf("DTU_Init_TaskHandle任务创建成功!\r\n");
	else
		printf(" DTU_Init_TaskHandle任务创建失败!\r\n");
	if(NULL != Wit_dat_TaskHandle)/* 创建成功 */
		printf("Wit_dat_TaskHandle任务创建成功!\r\n");
	else
		printf(" Wit_dat_TaskHandle任务创建失败!\r\n");
	if(NULL != Can_Rx_TaskHandle)/* 创建成功 */
		printf("Can_Rx_TaskHandle任务创建成功!\r\n");
	else
		printf(" Can_Rx_TaskHandle任务创建失败!\r\n");
	if(NULL != RB_Read_TaskHandle)/* 创建成功 */
		printf("RB_Read_TaskHandle任务创建成功!\r\n");
	else
		printf(" RB_Read_TaskHandle任务创建失败!\r\n");
	if(NULL != OilDisplay_TaskHandle)/* 创建成功 */
		printf("OilDisplay_TaskHandle任务创建成功!\r\n");
	else
		printf(" OilDisplay_TaskHandle任务创建失败!\r\n");
	if(NULL != Signal_4G_TaskHandle)/* 创建成功 */
		printf("Signal_4G_TaskHandle任务创建成功!\r\n");
	else
		printf(" Signal_4G_TaskHandle任务创建失败!\r\n");
	if(NULL != GPS_Init_TaskHandle)/* 创建成功 */
		printf("GPS_Init_TaskHandle任务创建成功!\r\n");
	else
		printf(" GPS_Init_TaskHandle任务创建失败!\r\n");
	if(NULL != GPS_Get_TaskHandle)/* 创建成功 */
		printf("GPS_Get_TaskHandle任务创建成功!\r\n");
	else
		printf(" GPS_Get_TaskHandle任务创建失败!\r\n");
	if(NULL != IWDG_TaskHandle)/* 创建成功 */
		printf("IWDG_TaskHandle任务创建成功!\r\n");
	else
		printf(" IWDG_TaskHandle任务创建失败!\r\n");
	if(NULL != Otheradc_taskHandle)/* 创建成功 */
		printf("Otheradc_taskHandle任务创建成功!\r\n");
	else
		printf(" Otheradc_taskHandle任务创建失败!\r\n");
	if(NULL != Cantx_Handle)/* 创建成功 */
		printf("Cantx_Handle任务创建成功!\r\n");
	else
		printf(" Cantx_Handle任务创建失败!\r\n");
	if(NULL != TyreSpeedTaskHandle)/* 创建成功 */
		printf("TyreSpeedTaskHandle任务创建成功!\r\n");
	else
		printf(" TyreSpeedTaskHandle任务创建失败!\r\n");
	if(NULL != SD_Init_taskHandle)/* 创建成功 */
		printf("SD_Init_taskHandle任务创建成功!\r\n");
	else
		printf(" SD_Init_taskHandle任务创建失败!\r\n");
  /* USER CODE END RTOS_EVENTS */
}

void Wit_Dat_Handle(void *argument)
{
  /* USER CODE BEGIN Wit_Dat_Handle */
  /* Infinite loop */
	uint8_t i,m,n;
	FRESULT res_flash;
	UINT wit_bw;
	uint8_t Wit_date[128] = {0};
	static uint8_t witnum = 0;
	float Sd_wit_dat[10][9]= {0};
	char Sd_wit[128] = {0};
  for(;;)
  {
		if(osEventFlagsWait (Vcu_Event1Handle, EVENTBIT_0,osFlagsWaitAny, osWaitForever)&EVENTBIT_0){
			CmdProcess();
			if(s_cDataUpdate)
			{
				for(i = 0; i < 3; i++){
					wit_dat1.fAcc[i] = sReg[AX+i] / 32768.0f * 16.0f;
					Accfloat_tx[i].value = wit_dat1.fAcc[i];
					wit_dat1.fGyro[i] = sReg[GX+i] / 32768.0f * 2000.0f;
					wit_dat1.fAngle[i] = sReg[Roll+i] / 32768.0f * 180.0f;
					Anglefloat_tx[i].value = wit_dat1.fAngle[i];
				}
				if(s_cDataUpdate & ACC_UPDATE)
				{
//					printf("acc:%.3f %.3f %.3f\r\n", wit_dat1.fAcc[0], wit_dat1.fAcc[1], wit_dat1.fAcc[2]);
					s_cDataUpdate &= ~ACC_UPDATE;
				}
				if(s_cDataUpdate & GYRO_UPDATE)
				{
//					printf("gyro:%.3f %.3f %.3f\r\n", wit_dat1.fGyro[0], wit_dat1.fGyro[1], wit_dat1.fGyro[2]);
					s_cDataUpdate &= ~GYRO_UPDATE;
				}
				if(s_cDataUpdate & ANGLE_UPDATE)
				{
//					printf("angle:%.3f %.3f %.3f\r\n", wit_dat1.fAngle[0], wit_dat1.fAngle[1], wit_dat1.fAngle[2]);
					s_cDataUpdate &= ~ANGLE_UPDATE;
				}
				if(s_cDataUpdate & MAG_UPDATE)
				{
//					printf("mag:%d %d %d\r\n", sReg[HX], sReg[HY], sReg[HZ]);
					s_cDataUpdate &= ~MAG_UPDATE;
				}
			}
			for(i = 0; i < 8; i++){
				if(i<4){
					wit_msg[0][i] = Anglefloat_tx[0].data[i];
				}else{
					wit_msg[0][i] = Anglefloat_tx[1].data[i-4];
				}
			}
			for(i = 0; i < 8; i++){
				if(i<4){
					wit_msg[1][i] = Anglefloat_tx[2].data[i];
				}else{
					wit_msg[1][i] = Accfloat_tx[0].data[i-4];
				}
			}
			for(i = 0; i < 8; i++){
				if(i<4){
					wit_msg[2][i] = Accfloat_tx[1].data[i];
				}else{
					wit_msg[2][i] = Accfloat_tx[2].data[i-4];
				}
			}
			osEventFlagsSet(Can_EventHandle, CAN_EVENTBIT_1);
			if(dtu_device1.Onenet_Off_flag == 0&&dtu_device1.st_flag == 0){
				OneNet_Send(Wit_date,Wit_Device_ID,sizeof(Wit_date));
			}
			for(m = 0;m<3;m++){
				switch(m){
					case(0):{
						for(n = 0;n<3;n++){
							Sd_wit_dat[witnum][n] = wit_dat1.fAcc[n];
						}
						break;
					}
					case(1):{
						for(n = 0;n<3;n++){
							Sd_wit_dat[witnum][n+3] = wit_dat1.fGyro[n];
						}
						break;
					}
					case(2):{
						for(n = 0;n<3;n++){
							Sd_wit_dat[witnum][n+6] = wit_dat1.fAngle[n];
						}
						break;
					}
					default:{
						printf("Sd_wit_dat error!!\r\n");
						break;
					}
				}
		 }
		 if((witnum++)>=10){
				witnum = 0;
				if(osEventFlagsGet (SD_EventHandle)&SD_EVENTBIT_2){
					res_flash = f_open(&SDFile, "0:/FWT_dat/witdat.txt",FA_OPEN_APPEND | FA_WRITE);
					if ( res_flash == FR_OK ){
//						printf("open FWT_dat/witdat.txt success!!\r\n");
						memset(Sd_wit, 0, sizeof(Sd_wit));
						if(RTC_Start_flag == 1){
							sprintf(Sd_wit,"\r\n%04d/%02d/%02d %02d:%02d:%02d",GetData.Year+2000,GetData.Month,GetData.Date,rtcTime.Hours,rtcTime.Minutes,rtcTime.Seconds);
						}else{
							sprintf(Sd_wit,"time interval : %dms\r\n",uwTick-uwtin[2]);
						}
						uwtin[2] = uwTick;
						f_write(&SDFile,Sd_wit,sizeof(Sd_wit),&wit_bw);
						for(uint8_t k = 0;k<10;k++){
							memset(Sd_wit, 0, sizeof(Sd_wit));
							sprintf(Sd_wit,"\r\nacc:%.3f  %.3f %.3f g\r\ngyro:%.3f %.3f %.3f\r\nangle:%.3f %.3f %.3f"\
									    ,Sd_wit_dat[k][0],Sd_wit_dat[k][1],Sd_wit_dat[k][2]\
											,Sd_wit_dat[k][3],Sd_wit_dat[k][4],Sd_wit_dat[k][5]\
											,Sd_wit_dat[k][6],Sd_wit_dat[k][7],Sd_wit_dat[k][8]);
							f_write(&SDFile,Sd_wit,sizeof(Sd_wit),&wit_bw);
						}
					}else{
						printf("open FWT_dat/witdat.txt fail (%d)!!",res_flash);
					}
					f_close(&SDFile);
				}
		 }
		 vTaskDelay(Wit_Dat_Handle_Delay);
		}
  }
  /* USER CODE END Wit_Dat_Handle */
}

void Can_Rx_Handle(void *argument)
{
  /* USER CODE BEGIN Can_Rx_Handle */
  /* Infinite loop */
  for(;;)
  {
		osSemaphoreAcquire(CanBinarySemHandle,osWaitForever);
    osDelay(1);
  }
  /* USER CODE END Can_Rx_Handle */
}

void RingBuffer_Read_Handle(void *argument)
{
  /* USER CODE BEGIN RingBuffer_Read_Handle */
  /* Infinite loop */

	uint8_t i = 0,j = 0;
//	char *token;
	char DTU_Csq[5] = {0};
	uint8_t CSQvalue = 0;
	uint8_t receive[35] = {0};
	uint8_t dtu_date[64] = {0};
  for(;;)
  {
		if(osEventFlagsGet (Vcu_Event1Handle)&EVENTBIT_1)
		{
			memset(receive, 0, sizeof(receive));
			osMessageQueueGet (UsartQueueHandle, receive, NULL, osWaitForever);
			if(strcmp((char *)receive,ONENET_COM_OFF)== 0)
			{
//			printf("data = %s\r\n",receive);
				dtu_device1.Onenet_Off_flag = 1;
			}
			else if(strcmp((char *)receive,ONENET_COM_ON)== 0)
			{
				dtu_device1.Onenet_Off_flag = 0;
			}
			else if((strstr((char *)receive, "+CSQ") == ((char *)receive+2)))
			{
				osKernelLock ();
				//\n+CSQ: 17,99
//				printf("%s\r\n",receive);
				for( i = 8;i<10;i++){
					DTU_Csq[j] = receive[i];
					j++;
					if(j >= 2){
					CSQvalue = atoi(DTU_Csq);
//					printf("%d\r\n",CSQvalue);
					if(CSQvalue > 14){
					dtu_device1.Network_size = 5;}
					else if(CSQvalue > 9&&CSQvalue <= 14){
					dtu_device1.Network_size = 4;}
					else if(CSQvalue > 5&&CSQvalue <= 9){
					dtu_device1.Network_size = 3;}
					else if(CSQvalue > 2&&CSQvalue <= 5){
					dtu_device1.Network_size = 2;}
					else if(CSQvalue > 1&&CSQvalue <= 2){
					dtu_device1.Network_size = 1;}
					else if(CSQvalue == 0){
					dtu_device1.Network_size = 0;}
					j = 0;
					}
				}
				osKernelUnlock ();
				if(dtu_device1.Onenet_Off_flag == 0&&dtu_device1.st_flag == 0){
						OneNet_Send(dtu_date,DTU_Device_ID,sizeof(dtu_date));
				}
				osEventFlagsSet(Can_EventHandle, CAN_EVENTBIT_8);
//				printf("Network_size\r\n");
			 }
		}
		 vTaskDelay(50);
	}
  /* USER CODE END RingBuffer_Read_Handle */
}

void OilDisplayment_Handle(void *argument)
{
  /* USER CODE BEGIN OilDisplayment_Handle */
  /* Infinite loop */
	uint32_t oildisplay_value,xjwy_1,xjwy_2,xjwy_3,xjwy_4,oil_yy;
	uint8_t oildisplay[128] = {0};
	uint8_t sdxjwydat[10][7] = {0};
	char sd_xjwy[128] = {0};
	static uint8_t sdxjwynum = 0;
	UINT xjwy_bw;
	FRESULT res_flash;
  for(;;)
  {
		if(ADC1_Flag == 1)
		{
			ADC1_Flag = 0;
      oildisplay_value = 0;
			xjwy_1 = 0; xjwy_2 = 0; xjwy_3 = 0; xjwy_4 = 0; oil_yy = 0;
			for(uint8_t i=0;i<60;){
			  xjwy_1+=adc1_value[i++];                       //左前
			  xjwy_2+=adc1_value[i++];                       //右前
				xjwy_3+=adc1_value[i++];                       //左后
			  xjwy_4+=adc1_value[i++];                       //右后
  			oil_yy+=adc1_value[i++];                       //油压
				oildisplay_value += adc1_value[i++];           //油门线位
			}
			Wy_dat.displacement_dat = oildisplay_value*5/4096;	    //oildisplay_value/10*50/4096
			Wy_dat.xjwy1_dat = xjwy_1*22.5/4096;
			Wy_dat.xjwy2_dat = xjwy_2*22.5/4096;
			Wy_dat.xjwy3_dat = xjwy_3*22.5/4096;
			Wy_dat.xjwy4_dat = xjwy_4*22.5/4096;
			Wy_dat.oilyy_dat[0] = (int)(oil_yy*2000/4096)/100;
			Wy_dat.oilyy_dat[1] = (int)(oil_yy*2000/4096)%100;
//			printf("oilyy_dat:%d mv\r\n",oil_yy*3300/40960);
//			printf("Wy_dat.xjwy1_dat:%d mm\r\n",Wy_dat.xjwy1_dat);
//			printf("Wy_dat.xjwy2_dat:%d mm\r\n",Wy_dat.xjwy2_dat);
//			printf("Wy_dat.xjwy3_dat:%d mm\r\n",Wy_dat.xjwy3_dat);
//			printf("Wy_dat.xjwy4_dat:%d mm\r\n",Wy_dat.xjwy4_dat);
//			printf("displacement_dat:%d\r\n",Wy_dat.displacement_dat);
			sdxjwydat[sdxjwynum][0] = xjwy_msg[0] = Wy_dat.xjwy1_dat;
			sdxjwydat[sdxjwynum][1] = xjwy_msg[1] = Wy_dat.xjwy2_dat;
			sdxjwydat[sdxjwynum][2] = xjwy_msg[2] = Wy_dat.xjwy3_dat;
			sdxjwydat[sdxjwynum][3] = xjwy_msg[3] = Wy_dat.xjwy4_dat;
			sdxjwydat[sdxjwynum][4] = xjwy_msg[4] = Wy_dat.displacement_dat;
			sdxjwydat[sdxjwynum][5] = xjwy_msg[5] = Wy_dat.oilyy_dat[0];
			sdxjwydat[sdxjwynum][6] = xjwy_msg[6] = Wy_dat.oilyy_dat[1];
			osEventFlagsSet(Can_EventHandle, CAN_EVENTBIT_6);
			if(dtu_device1.Onenet_Off_flag == 0&&dtu_device1.st_flag == 0){
				OneNet_Send(oildisplay,XJ_Device_ID,sizeof(oildisplay));
			}
			if((sdxjwynum++)>=10){
				sdxjwynum = 0;
				if(osEventFlagsGet (SD_EventHandle)&SD_EVENTBIT_1){
					res_flash = f_open(&SDFile, "0:/FWT_dat/xjwydat.txt",FA_OPEN_APPEND | FA_WRITE);
					if ( res_flash == FR_OK ){
//						printf("open FWT_dat/xjwydat.txt success!!\r\n");
						memset(sd_xjwy, 0, sizeof(sd_xjwy));
						if(RTC_Start_flag == 1){
							sprintf(sd_xjwy,"\r\n%04d/%02d/%02d %02d:%02d:%02d",GetData.Year+2000,GetData.Month,GetData.Date,rtcTime.Hours,rtcTime.Minutes,rtcTime.Seconds);
						}else{
							sprintf(sd_xjwy,"time interval : %dms\r\n",uwTick-uwtin[0]);
						}
						uwtin[0] = uwTick;
						f_write(&SDFile,sd_xjwy,sizeof(sd_xjwy),&xjwy_bw);
						for(uint8_t i = 0;i<10;i++){
							memset(sd_xjwy, 0, sizeof(sd_xjwy));
							sprintf(sd_xjwy,"\r\nxj1 = %d mm ,xj2 = %d mm ,xj3 = %d mm ,xj4 = %d mm ,zd = %2.3lf mpa, ym = %d mm",sdxjwydat[i][0],\
							sdxjwydat[i][1],sdxjwydat[i][2],sdxjwydat[i][3],(sdxjwydat[i][5]*100+sdxjwydat[i][6])*1.0/1000\
							,sdxjwydat[i][4]);
							f_write(&SDFile,sd_xjwy,sizeof(sd_xjwy),&xjwy_bw);
						}
					}else{
						printf("open FWT_dat/xjwydat.txt fail (%d)!!",res_flash);
					}
					f_close(&SDFile);
				}
			}
			HAL_ADC_Start_DMA(&hadc1,adc1_value,sizeof(adc1_value)/4);
		}

    osDelay(OD_Handle_Delay);
  }
  /* USER CODE END OilDisplayment_Handle */
}

void DTU_Init_Handle(void *argument)
{
  /* USER CODE BEGIN DTU_Init_Handle */
  /* Infinite loop */
	uint16_t timeout = 0;
	int ret;
  for(;;)
  {
		my_mem_init(SRAMIN);
		p_uart2_rxbuf = RingBuffer_Malloc(1024);        /*从内存池中分配1K的内存给串口3接收DTU数据*/
		printf("Wait for Cat1 DTU to start, wait 10s.... \r\n");
		while( timeout <= 10 ){   /* 等待Cat1 DTU启动，需要等待5-6s才能启动 */
				ret = dtu_config_init(DTU_WORKMODE_ONENET);    /*初始化DTU工作参数*/
				if( ret == 0 ){
					osEventFlagsSet(Vcu_Event1Handle, EVENTBIT_3);
					printf("**************************************************************************\r\n");
					printf("Cat1 DTU Init Success \r\n");
					printf("**************************************************************************\r\n\r\n");
					break;
				}
				timeout++;
				osDelay(1000);
		}
		if( timeout > 10 ){   /* 超时 */
			printf("**************************************************************************\r\n");
			printf("ATK-DTU Init Fail ...\r\n");
			printf("**************************************************************************\r\n\r\n");
		}
    if((osEventFlagsGet (Vcu_Event1Handle)&EVENTBIT_3)){
			osEventFlagsSet(Vcu_Event1Handle, EVENTBIT_2);
		}
		vTaskDelete(DTU_Init_TaskHandle);
	}
  /* USER CODE END DTU_Init_Handle */
}

void Signal_4G_Handle(void *argument)
{
  /* USER CODE BEGIN Signal_4G_Handle */
  /* Infinite loop */
	uint8_t j = 0;
	int ret;
  for(;;)
  {
			if(osEventFlagsWait (Vcu_Event1Handle, EVENTBIT_2,osFlagsNoClear, osWaitForever)&EVENTBIT_2){
//				printf("%d\r\n",(osEventFlagsGet(Vcu_Event1Handle)&EVENTBIT_3));
				if(osEventFlagsGet (Vcu_Event1Handle)&EVENTBIT_3){
					osMutexAcquire(MqttMutexHandle,osWaitForever);
					dtu_device1.st_flag = 1;
					while(j<5){
						osEventFlagsClear(Vcu_Event1Handle, EVENTBIT_1);
						/*1.DTU进入配置状态*/
						ret = dtu_enter_configmode();
						if ( ret != 0 ){
							printf("DTU enter set mode failed !\r\n");
							vTaskDelay(10);
							j++;
						}
						else{
							printf("DTU enter set mode !\r\n");
							osEventFlagsClear(Vcu_Event1Handle, EVENTBIT_3);
							send_data_to_dtu("AT+CSQ\r\n", strlen("AT+CSQ\r\n"));
							break;
						}
					}
					dtu_device1.st_flag = 0;
					j = 0;
					osEventFlagsSet(Vcu_Event1Handle, EVENTBIT_1);
					osMutexRelease(MqttMutexHandle);
				}
			}
		osDelay(DTU_Signal_Delay);
  }
  /* USER CODE END Signal_4G_Handle */
}

void GPS_Init_Handle(void *argument)
{
  /* USER CODE BEGIN GPS_Init_Handle */
  /* Infinite loop */
	uint8_t key=0xff;
  for(;;)
  {
		if(Ublox_Cfg_Rate(400,1)!=0)               //设置定位信息更新速度为400ms,顺便判断GPS模块是否在位.
	  {
			printf("WT-GPS_BD Setting...\r\n");
			while((Ublox_Cfg_Rate(400,1)!=0)&&key){	//持续判断,直到可以检查到WT-GPS_BD,且数据保存成功
				Ublox_Cfg_Tp(500000,100000,1);	//设置PPS为1秒钟输出1次,脉冲宽度为100ms
				Ublox_Cfg_Prt(115200);
				key=Ublox_Cfg_Cfg_Save();		//保存配置
			}
			printf("WT-GPS_BD Set Done!!\r\n");
			osDelay(1);
		}
		osEventFlagsSet(Vcu_Event1Handle, EVENTBIT_8);
    vTaskDelete(GPS_Init_TaskHandle);
  }
  /* USER CODE END GPS_Init_Handle */
}

void GPS_Get_Handle(void *argument)
{
  /* USER CODE BEGIN GPS_Get_Handle */
  /* Infinite loop */
  for(;;)
  {
		if(osEventFlagsGet (Vcu_Event1Handle)&EVENTBIT_8){
			if(USART3_RX_STA&0X8000){		//接收到一次数据了
				USART3_RX_STA=0;		   	//启动下一次接收
				GPS_Analysis(&gpsx,(uint8_t*)USART3_RX_BUF);//分析字符串
				Gps_Msg_Show();				//显示信息
			}
		}
		osDelay(GPS_Handle_Delay);
  }
  /* USER CODE END GPS_Get_Handle */
}

void IWDG_Handle(void *argument)
{
  /* USER CODE BEGIN IWDG_Handle */
  /* Infinite loop */
  for(;;)
  {
//		printf("iwdg\r\n");
		__HAL_IWDG_RELOAD_COUNTER(&hiwdg);
    osDelay(500);
  }
  /* USER CODE END IWDG_Handle */
}

void Oadc_Handle(void *argument)
{
  /* USER CODE BEGIN Oadc_Handle */
  /* Infinite loop */
  uint32_t battery_capacity = 0,oil_capacity = 0;
	uint32_t count_som = 0;
	uint8_t Oil_count[110]= {0};
	uint16_t High[8] = {0};                       //油量高度数组
	uint8_t Oil = 0;							 							  //油量
	static uint8_t memory_oil = 0;
	static uint8_t High_Count = 0;
	static uint16_t Oil_i = 0,df = 0;
	static uint8_t first_flag = 1;
	static uint8_t af = 0,bf = 0,cf = 0;
  for(;;)
  {
		if(ADC2_Flag == 1)
		{
			ADC2_Flag = 0;
			oil_capacity = 0;battery_capacity = 0;
			for(uint8_t i=0;i<20;){
				oil_capacity += adc2_value[i++];
				battery_capacity += adc2_value[i++];
		  }
//			printf("battery_capacity = %d\r\noil_capacity = %d\r\n",battery_capacity*330/4096,oil_capacity*330/4096);
			if(first_flag == 1)             //采样首次油量数据
			{
				oil_first:
				/* 获取各通道ADC采集值 */
				oil_capacity = oil_capacity/10;
				/* 油量高度与检测电压的关系 High(mm) = Volt(mv) / 5 */
				if(oil_capacity > 100 && oil_capacity < 1400)//&& Oil_dat
				{
//					printf("adc = %d\r\n",Oil_dat);
					High[High_Count] = (oil_capacity * 3300*2.1) / 4095 / 5;
					High_Count++;
					if(High_Count >= 100)
					{
						for(uint8_t i = 0; i < High_Count-1; i++){
							for(uint8_t j = i+1; j < High_Count; j++){
								if(High[j] < High[i]){
									uint16_t temp = High[i];
									High[i] = High[j];
									High[j] = temp;
								}
							}
						}
//						printf("High[High_Count / 2] = %d\r\n",High[High_Count / 2]);
						Oil = (High[High_Count / 2] * 100) / TANK_HEIGHT;           //去中位数
//						printf("Oil = %d",Oil);
						High_Count = 0;
//						printf("Oil = %d",Oil);
						if(Oil <= 99 && Oil >=30){
							Oil_base_dat = Oil;
							first_flag = 0;
							memory_oil = Oil_base_dat;
							__HAL_TIM_SET_COUNTER(&htim13,0);
							__HAL_TIM_ENABLE(&htim13);                                     // 使能计数器
						}
						else if(Oil < 30){
							if(af <= 20){
								af++;
								goto oil_first;
							}
							af = 0;
							Oil_base_dat = 0;
							first_flag = 2;
						}
						else if(Oil > 99){
							Oil_base_dat = 99;
							first_flag = 0;
							memory_oil = Oil_base_dat;
							__HAL_TIM_SET_COUNTER(&htim13,0);
							__HAL_TIM_ENABLE(&htim13);                                     // 使能计数器
						}
					}
				}
				else if(af > 20){
					first_flag = 2;
					Oil_base_dat = 0;
					af = 0;
				}
				else{
					af++;
				}
			}
			else if(first_flag == 0)                                             //定时器校验油量数据
			{
					/* 获取各通道ADC采集值 */
				oil_capacity = oil_capacity/10;
				/* 油量高度与检测电压的关系 High(mm) = Volt(mv) / 5 */
				if(oil_capacity > 350)    /* 没测到液体时小于50mv，所以去350 */
				{
					High[High_Count] = (oil_capacity * 3300*2.1) / 4095 / 5;
					High_Count++;
					if(High_Count >= 5){
						for(uint8_t i = 0; i < High_Count-1; i++){
							for(int8_t j = i+1; j < High_Count; j++){
								if(High[j] < High[i]){
									int16_t temp = High[i];
									High[i] = High[j];
									High[j] = temp;
								}
							}
						}
						Oil = (High[High_Count / 2] * 100) / TANK_HEIGHT;
						High_Count = 0;
					}
				}
				if(Oil < memory_oil+10&&Oil > memory_oil-10)
				{
					Oil_count[Oil_i++] = Oil;
				}
				if(Oil_i >= 50)
				{
					count_som = 0;
					for(uint8_t i = 0; i < 50; i++){
						count_som += Oil_count[i];
					}
					if(count_som/50 >= memory_oil){bf++;}
					else if(count_som/50 < memory_oil){df += count_som/50,cf++;}
					if(bf >= 5){                                      //测量值大于Oil_base_dat
						 __HAL_TIM_DISABLE(&htim13);																									// 失能计数器
						 bf = 0;cf = 0;
					}
					else if(cf >= 5){
						memory_oil = df/5;
						__HAL_TIM_SET_COUNTER(&htim13,0);
						__HAL_TIM_ENABLE(&htim13);																									// 使能计数器
						cf = 0;bf = 0;
					}
					Oil_i = 0;
				}
//				printf("volt : %d",(Oil_dat * 3300) / 4095);
//				printf(" oil：%d\r\n ",Oil);
			}
			battery_capacity = battery_capacity*330/4096;                    //电池电量采样
			if(battery_capacity >3235){
				oadc_msg[0] = 6;
			}else if( battery_capacity > 3160&&battery_capacity < 3235){
				oadc_msg[0] = 5;
			}else if( battery_capacity > 3080&&battery_capacity < 3160){
				oadc_msg[0] = 4;
			}else if( battery_capacity > 2990&&battery_capacity < 3080){
				oadc_msg[0] = 3;
			}else if( battery_capacity > 2910&&battery_capacity < 2990){
				oadc_msg[0] = 2;
			}else if( battery_capacity > 2840&&battery_capacity < 2910){
				oadc_msg[0] = 1;
			}else if(battery_capacity < 2810){
				oadc_msg[0] = 0;
			}
//			printf("battery_capacity = %d\r\n",oadc_msg[0]);
			oadc_msg[1] = Oil_base_dat;
			osEventFlagsSet(Can_EventHandle, CAN_EVENTBIT_7);
//			if(dtu_device1.Onenet_Off_flag == 0&&dtu_device1.st_flag == 0){
//				OneNet_Send(oildisplay,XJ1_Device_ID,sizeof(oildisplay));
//			}
			HAL_ADC_Start_DMA(&hadc2,adc2_value,sizeof(adc2_value)/4);
		}
		if(first_flag == 1){
			osDelay(10);
		}else{
			osDelay(ADC_Handle_Delay);
		}
  }
  /* USER CODE END Oadc_Handle */
}

void Cantx_Handle(void *argument)
{
  /* USER CODE BEGIN Cantx_Handle */
  /* Infinite loop */
	uint32_t can_tx_mailbox;
	uint8_t canovertime = 0;
	CAN_TxHeaderTypeDef TxMessage;
	TxMessage.ExtId=0;
	TxMessage.IDE=CAN_ID_STD;
	TxMessage.RTR=CAN_RTR_DATA;
	TxMessage.TransmitGlobalTime=DISABLE;
  for(;;)
  {
		#define candelay 5
		//九轴数据
		if(osEventFlagsGet (Can_EventHandle)&CAN_EVENTBIT_1){
			osEventFlagsClear (Can_EventHandle, CAN_EVENTBIT_1);
			TxMessage.StdId=Wit_StdId_xy;
			TxMessage.DLC=sizeof(wit_msg[0]);
			while(HAL_CAN_GetTxMailboxesFreeLevel(&hcan1) < 1){
				if(canovertime++ >= 5){
					break;
				}else{
					osDelay(1);
				}
			}
			if(HAL_CAN_AddTxMessage(&hcan1,&TxMessage,wit_msg[0],&can_tx_mailbox) != HAL_OK){
				printf ("data sending failure！\r\n");
			}
			osDelay(candelay);
			TxMessage.StdId=Wit_StdId_xy+1;
			TxMessage.DLC=sizeof(wit_msg[1]);
			while(HAL_CAN_GetTxMailboxesFreeLevel(&hcan1) < 1){
				if(canovertime++ >= 5){
					break;
				}else{
					osDelay(1);
				}
			}
			if(HAL_CAN_AddTxMessage(&hcan1,&TxMessage,wit_msg[1],&can_tx_mailbox) != HAL_OK){
				printf ("data sending failure！\r\n");
			}
			osDelay(candelay);
			TxMessage.StdId=Wit_StdId_xy+2;
			TxMessage.DLC=sizeof(wit_msg[2]);
			while(HAL_CAN_GetTxMailboxesFreeLevel(&hcan1) < 1){
				if(canovertime++ >= 5){
					break;
				}else{
					osDelay(1);
				}
			}
			if(HAL_CAN_AddTxMessage(&hcan1,&TxMessage,wit_msg[2],&can_tx_mailbox) != HAL_OK){
				printf ("data sending failure！\r\n");
			}
			osDelay(candelay);
		}
		//轮速速度数据
		if(osEventFlagsGet (Can_EventHandle)&CAN_EVENTBIT_2){
			osEventFlagsClear (Can_EventHandle, CAN_EVENTBIT_2);
			canovertime = 0;
			TxMessage.StdId=Tyre_StdId;
			TxMessage.DLC=sizeof(tyre_msg);
			while(HAL_CAN_GetTxMailboxesFreeLevel(&hcan1) < 1){
				if(canovertime++ >= 5){
					break;
				}
				else{
					osDelay(1);
				}
			}
			if(HAL_CAN_AddTxMessage(&hcan1,&TxMessage,tyre_msg,&can_tx_mailbox) != HAL_OK){
				printf ("data sending failure！\r\n");
			}
			osDelay(candelay);
		}
		//gps速度数据
		if(osEventFlagsGet (Can_EventHandle)&CAN_EVENTBIT_4){
			osEventFlagsClear (Can_EventHandle, CAN_EVENTBIT_4);
			canovertime = 0;
			TxMessage.StdId=GPS_StdId;
			TxMessage.DLC=sizeof(speedfloat_tx.data);
			while(HAL_CAN_GetTxMailboxesFreeLevel(&hcan1) < 1){
				if(canovertime++ >= 5){
					break;
				}
				else{
					osDelay(1);
				}
			}
			if(HAL_CAN_AddTxMessage(&hcan1,&TxMessage,speedfloat_tx.data,&can_tx_mailbox) != HAL_OK){
				printf ("data sending failure！\r\n");
			}
			osDelay(candelay);
		}
		//GPS实时时间数据
		if(osEventFlagsGet (Can_EventHandle)&CAN_EVENTBIT_5){
			osEventFlagsClear (Can_EventHandle, CAN_EVENTBIT_5);
			canovertime = 0;
			TxMessage.StdId=CLK_StdId;
			TxMessage.DLC=sizeof(Clkvalue);
			while(HAL_CAN_GetTxMailboxesFreeLevel(&hcan1) < 1){
				if(canovertime++ >= 5){
					break;
				}
				else{
					osDelay(1);
				}
			}
			if(HAL_CAN_AddTxMessage(&hcan1,&TxMessage,Clkvalue,&can_tx_mailbox) != HAL_OK){
				printf ("data sending failure！\r\n");
			}
			osDelay(candelay);
		}
		//悬架位移数据
		if(osEventFlagsGet (Can_EventHandle)&CAN_EVENTBIT_6){
			osEventFlagsClear (Can_EventHandle, CAN_EVENTBIT_6);
			canovertime = 0;
			TxMessage.StdId=XJWY_StdId;
			TxMessage.DLC=sizeof(xjwy_msg);
			while(HAL_CAN_GetTxMailboxesFreeLevel(&hcan1) < 1){
				if(canovertime++ >= 5){
					break;
				}
				else{
					osDelay(1);
				}
			}
			if(HAL_CAN_AddTxMessage(&hcan1,&TxMessage,xjwy_msg,&can_tx_mailbox) != HAL_OK){
				printf ("data sending failure！\r\n");
			}
			osDelay(candelay);
		}
		//电池电量，油量
		if(osEventFlagsGet (Can_EventHandle)&CAN_EVENTBIT_7){
			osEventFlagsClear (Can_EventHandle, CAN_EVENTBIT_7);
			canovertime = 0;
			TxMessage.StdId=OADC_StdId;
			TxMessage.DLC=sizeof(oadc_msg);
			while(HAL_CAN_GetTxMailboxesFreeLevel(&hcan1) < 1){
				if(canovertime++ >= 5){
					break;
				}
				else{
					osDelay(1);
				}
			}
			if(HAL_CAN_AddTxMessage(&hcan1,&TxMessage,oadc_msg,&can_tx_mailbox) != HAL_OK){
				printf ("data sending failure！\r\n");
			}
			osDelay(candelay);
		}
		//4G信号
		if(osEventFlagsGet (Can_EventHandle)&CAN_EVENTBIT_8){
			osEventFlagsClear (Can_EventHandle, CAN_EVENTBIT_8);
			canovertime = 0;
			TxMessage.StdId=DTU_StdId;
			TxMessage.DLC=sizeof(dtu_device1.Network_size);
//			printf("dtu_device1.Network_size = %d\r\n",dtu_device1.Network_size);
			while(HAL_CAN_GetTxMailboxesFreeLevel(&hcan1) < 1){
				if(canovertime++ >= 5){
					break;
				}
				else{
					osDelay(1);
				}
			}
			if(HAL_CAN_AddTxMessage(&hcan1,&TxMessage,&dtu_device1.Network_size,&can_tx_mailbox) != HAL_OK){
				printf ("data sending failure！\r\n");
			}
			osDelay(candelay);
		}
		osDelay(1);
	}
  /* USER CODE END Cantx_Handle */
}

void TyreSpeed_Handle(void *argument)
{
  /* USER CODE BEGIN TyreSpeed_Handle */
  /* Infinite loop */
	uint8_t tyrespeed[64] = {0};
	uint16_t sdtyrespeed[5][11] = {0};
	static uint8_t sdnum[5] = {0};
	char sd_tyre[64] = {0};
	UINT tyre1_bw,tyre2_bw,tyre3_bw,tyre4_bw,moderator_bw;
	FRESULT res_flash;
  for(;;)
  {
		/* 左前轮 */
		if(osEventFlagsGet (MT_EventHandle)&MT_EVENTBIT_1){
			osEventFlagsClear (MT_EventHandle, MT_EVENTBIT_1);
			if (mtspeed1.Endup_Flag != 0)                         //轮速信号捕获完成
			{
				if(mtspeed1.Total_Time_M1 == 0){
					mtspeed1.Rotate_Speed = 0;
					mtspeed1.Total_Time_M2 = 0;
					mtspeed1.Endup_Flag = 0;
				}
				else{
					mtspeed1.Endup_Flag = 0;
					mtspeed1.Rotate_Speed = (5000.0*60*mtspeed1.Total_Time_M1)/(F_TOOTH_NUM*mtspeed1.Total_Time_M2);    //计算转速(r/min)   M/T算法公式
					sdtyrespeed[0][sdnum[0]++] = mtspeed1.Rotate_Speed;
					if(sdnum[0]>=10){
						sdnum[0] = 0;
						if(osEventFlagsGet (SD_EventHandle)&SD_EVENTBIT_3){
							res_flash = f_open(&SDFile, "0:/FWT_dat/tyrespeed/tyrespeed1.txt",FA_OPEN_APPEND | FA_WRITE);
							if ( res_flash == FR_OK ){
//								printf("FWT_dat/tyrespeed/tyrespeed1.txt open success!");
								memset(sd_tyre, 0, sizeof(sd_tyre));
								if(RTC_Start_flag == 1){
									sprintf(sd_tyre,"\r\n%04d/%02d/%02d %02d:%02d:%02d",GetData.Year+2000,GetData.Month,GetData.Date,rtcTime.Hours,rtcTime.Minutes,rtcTime.Seconds);
								}else{
									sprintf(sd_tyre,"time interval : %dms\r\n",uwTick-uwtin[3]);
								}
								uwtin[3] = uwTick;
								f_write(&SDFile,sd_tyre,sizeof(sd_tyre),&tyre1_bw);
								memset(sd_tyre, 0, sizeof(sd_tyre));
								sprintf(sd_tyre,"\r\ntyre1 = %d r/min , %d r/min , %d r/min , %d r/min , %d r/min",sdtyrespeed[0][0],sdtyrespeed[0][1],sdtyrespeed[0][2],sdtyrespeed[0][3],sdtyrespeed[0][4]);
								f_write(&SDFile,sd_tyre,sizeof(sd_tyre),&tyre1_bw);
								memset(sd_tyre, 0, sizeof(sd_tyre));
								sprintf(sd_tyre,"\r\ntyre1 = %d r/min , %d r/min , %d r/min , %d r/min , %d r/min",sdtyrespeed[0][5],sdtyrespeed[0][6],sdtyrespeed[0][7],sdtyrespeed[0][8],sdtyrespeed[0][9]);
								f_write(&SDFile,sd_tyre,sizeof(sd_tyre),&tyre1_bw);
							}
							else{
								printf("FWT_dat/tyrespeed/tyrespeed1.txt open fail!(%d)",res_flash);
							}
							f_close(&SDFile);
						}
					}
//          printf(" SPEED1 = %d,M1 = %d,M2 =  %d\r\n ",mtspeed1.Rotate_Speed,mtspeed1.Total_Time_M1,mtspeed1.Total_Time_M2);
					mtspeed1.Total_Time_M1 = 0;
					mtspeed1.Total_Time_M2 = 0;
				}
				mtspeed1.startcount = 0;
				HAL_TIM_IC_Start_IT(&htim2,TIM_CHANNEL_2);
			}
		}
		/* 右后轮 */
		if(osEventFlagsGet (MT_EventHandle)&MT_EVENTBIT_2){
			osEventFlagsClear (MT_EventHandle, MT_EVENTBIT_2);
			if (mtspeed2.Endup_Flag != 0)                         //轮速信号捕获完成
			{
				if(mtspeed2.Total_Time_M1 == 0){
					mtspeed2.Rotate_Speed = 0;
					mtspeed2.Total_Time_M2 = 0;
					mtspeed2.Endup_Flag = 0;
				}
				else{
					mtspeed2.Endup_Flag = 0;
					mtspeed2.Rotate_Speed = (5000.0*60*mtspeed2.Total_Time_M1)/(Q_TOOTH_NUM*mtspeed2.Total_Time_M2);    //计算转速(r/min)  M/T算法公式
  				printf(" SPEED2 = %d,M1 = %d,M2 =  %d\r\n ",mtspeed2.Rotate_Speed,mtspeed2.Total_Time_M1,mtspeed2.Total_Time_M2);
					sdtyrespeed[1][sdnum[1]++] = mtspeed2.Rotate_Speed;
					if(sdnum[1]>=10){
						sdnum[1] = 0;
						if(osEventFlagsGet (SD_EventHandle)&SD_EVENTBIT_3){
							res_flash = f_open(&SDFile, "0:/FWT_dat/tyrespeed/tyrespeed2.txt",FA_OPEN_APPEND | FA_WRITE);
							if ( res_flash == FR_OK ){
//								printf("FWT_dat/tyrespeed/tyrespeed2.txt open success!");
								memset(sd_tyre, 0, sizeof(sd_tyre));
								if(RTC_Start_flag == 1){
									sprintf(sd_tyre,"\r\n%04d/%02d/%02d %02d:%02d:%02d",GetData.Year+2000,GetData.Month,GetData.Date,rtcTime.Hours,rtcTime.Minutes,rtcTime.Seconds);
								}else{
									sprintf(sd_tyre,"time interval : %dms\r\n",uwTick-uwtin[4]);
								}
								uwtin[4] = uwTick;
								f_write(&SDFile,sd_tyre,sizeof(sd_tyre),&tyre2_bw);
								memset(sd_tyre, 0, sizeof(sd_tyre));
								sprintf(sd_tyre,"\r\ntyre2 = %d r/min , %d r/min , %d r/min , %d r/min , %d r/min",sdtyrespeed[1][0],sdtyrespeed[1][1],sdtyrespeed[1][2],sdtyrespeed[1][3],sdtyrespeed[1][4]);
								f_write(&SDFile,sd_tyre,sizeof(sd_tyre),&tyre2_bw);
								memset(sd_tyre, 0, sizeof(sd_tyre));
								sprintf(sd_tyre,"\r\ntyre2 = %d r/min , %d r/min , %d r/min , %d r/min , %d r/min",sdtyrespeed[1][5],sdtyrespeed[1][6],sdtyrespeed[1][7],sdtyrespeed[1][8],sdtyrespeed[1][9]);
								f_write(&SDFile,sd_tyre,sizeof(sd_tyre),&tyre2_bw);
							}
							else
							{
								printf("FWT_dat/tyrespeed/tyrespeed2.txt open fail!(%d)",res_flash);
							}
							f_close(&SDFile);
						}
					}
					mtspeed2.Total_Time_M1 = 0;
					mtspeed2.Total_Time_M2 = 0;
				}
				mtspeed2.startcount = 0;
				HAL_TIM_IC_Start_IT(&htim2,TIM_CHANNEL_1);
			}
		}
		/* 右前轮 */
		if(osEventFlagsGet (MT_EventHandle)&MT_EVENTBIT_3){
			osEventFlagsClear (MT_EventHandle, MT_EVENTBIT_3);
			if (mtspeed3.Endup_Flag != 0)                         //轮速信号捕获完成
			{
				if(mtspeed3.Total_Time_M1 == 0){
					mtspeed3.Rotate_Speed = 0;
					mtspeed3.Total_Time_M2 = 0;
					mtspeed3.Endup_Flag = 0;
				}
				else{
					mtspeed3.Endup_Flag = 0;
					mtspeed3.Rotate_Speed = (5000.0*60*mtspeed3.Total_Time_M1)/(F_TOOTH_NUM*mtspeed3.Total_Time_M2);    //计算转速(r/min)
					sdtyrespeed[2][sdnum[2]++] = mtspeed3.Rotate_Speed;
					if(sdnum[2]>=10){
						sdnum[2] = 0;
						if(osEventFlagsGet (SD_EventHandle)&SD_EVENTBIT_3){
							res_flash = f_open(&SDFile, "0:/FWT_dat/tyrespeed/tyrespeed3.txt",FA_OPEN_APPEND | FA_WRITE);
							if ( res_flash == FR_OK ){
//								printf("FWT_dat/tyrespeed/tyrespeed3.txt open success!");
								memset(sd_tyre, 0, sizeof(sd_tyre));
								if(RTC_Start_flag == 1){
									sprintf(sd_tyre,"\r\n%04d/%02d/%02d %02d:%02d:%02d",GetData.Year+2000,GetData.Month,GetData.Date,rtcTime.Hours,rtcTime.Minutes,rtcTime.Seconds);
								}else{
									sprintf(sd_tyre,"time interval : %dms\r\n",uwTick-uwtin[5]);
								}
								uwtin[5] = uwTick;
								f_write(&SDFile,sd_tyre,sizeof(sd_tyre),&tyre3_bw);
								memset(sd_tyre, 0, sizeof(sd_tyre));
								sprintf(sd_tyre,"\r\ntyre3 = %d r/min , %d r/min , %d r/min , %d r/min , %d r/min",sdtyrespeed[2][0],sdtyrespeed[2][1],sdtyrespeed[2][2],sdtyrespeed[2][3],sdtyrespeed[2][4]);
								f_write(&SDFile,sd_tyre,sizeof(sd_tyre),&tyre3_bw);
								memset(sd_tyre, 0, sizeof(sd_tyre));
								sprintf(sd_tyre,"\r\ntyre3 = %d r/min , %d r/min , %d r/min , %d r/min , %d r/min",sdtyrespeed[2][5],sdtyrespeed[2][6],sdtyrespeed[2][7],sdtyrespeed[2][8],sdtyrespeed[2][9]);
								f_write(&SDFile,sd_tyre,sizeof(sd_tyre),&tyre3_bw);
							}
							else{
								printf("FWT_dat/tyrespeed/tyrespeed3.txt open fail!(%d)",res_flash);
							}
							f_close(&SDFile);
						}
					}
//					printf(" SPEED3 = %d,M1 = %d,M2 =  %d\r\n ",mtspeed3.Rotate_Speed,mtspeed3.Total_Time_M1,mtspeed3.Total_Time_M2);
					mtspeed3.Total_Time_M1 = 0;
					mtspeed3.Total_Time_M2 = 0;
				}
				mtspeed3.startcount = 0;
				HAL_TIM_IC_Start_IT(&htim5,TIM_CHANNEL_1);
//				printf("TIM_CHANNEL_2\r\n");
			}
		}
		/* 左后轮 */
		if(osEventFlagsGet (MT_EventHandle)&MT_EVENTBIT_4){
			osEventFlagsClear (MT_EventHandle, MT_EVENTBIT_4);
			if (mtspeed4.Endup_Flag != 0)                         //轮速信号捕获完成
			{
				if(mtspeed4.Total_Time_M1 == 0){
					mtspeed4.Rotate_Speed = 0;
					mtspeed4.Total_Time_M2 = 0;
					mtspeed4.Endup_Flag = 0;
				}
				else{
					mtspeed4.Endup_Flag = 0;
					if(time3_over1 == 0){
					mtspeed4.Rotate_Speed = (5000.0*60*mtspeed4.Total_Time_M1)/(Q_TOOTH_NUM*mtspeed4.Total_Time_M2);    //计算转速(r/min)
//					printf(" SPEED4 = %d,M1 = %d,M2 =  %d\r\n ",mtspeed4.Rotate_Speed,mtspeed4.Total_Time_M1,mtspeed4.Total_Time_M2);
					}else{
						time3_over1 = 0;
						mtspeed4.memory_value = 0;
					}
					sdtyrespeed[3][sdnum[3]++] = mtspeed4.Rotate_Speed;
					if(sdnum[3]>=10){
						sdnum[3] = 0;
						if(osEventFlagsGet (SD_EventHandle)&SD_EVENTBIT_3){
							res_flash = f_open(&SDFile, "0:/FWT_dat/tyrespeed/tyrespeed4.txt",FA_OPEN_APPEND | FA_WRITE);
							if ( res_flash == FR_OK ){
//								printf("FWT_dat/tyrespeed/tyrespeed4.txt open success!");
								memset(sd_tyre, 0, sizeof(sd_tyre));
								if(RTC_Start_flag == 1){
									sprintf(sd_tyre,"\r\n%04d/%02d/%02d %02d:%02d:%02d",GetData.Year+2000,GetData.Month,GetData.Date,rtcTime.Hours,rtcTime.Minutes,rtcTime.Seconds);
								}else{
									sprintf(sd_tyre,"time interval : %dms\r\n",uwTick-uwtin[6]);
								}
								uwtin[6] = uwTick;
								f_write(&SDFile,sd_tyre,sizeof(sd_tyre),&tyre4_bw);
								memset(sd_tyre, 0, sizeof(sd_tyre));
								sprintf(sd_tyre,"\r\ntyre4 = %d r/min , %d r/min , %d r/min , %d r/min , %d r/min",sdtyrespeed[3][0],sdtyrespeed[3][1],sdtyrespeed[3][2],sdtyrespeed[3][3],sdtyrespeed[3][4]);
								f_write(&SDFile,sd_tyre,sizeof(sd_tyre),&tyre4_bw);
								memset(sd_tyre, 0, sizeof(sd_tyre));
								sprintf(sd_tyre,"\r\ntyre4 = %d r/min , %d r/min , %d r/min , %d r/min , %d r/min",sdtyrespeed[3][5],sdtyrespeed[3][6],sdtyrespeed[3][7],sdtyrespeed[3][8],sdtyrespeed[3][9]);
								f_write(&SDFile,sd_tyre,sizeof(sd_tyre),&tyre4_bw);
							}
							else
							{
								printf("FWT_dat/tyrespeed/tyrespeed4.txt open fail!(%d)",res_flash);
							}
							f_close(&SDFile);
						}
					}
//					printf(" SPEED4 = %d,M1 = %d,M2 =  %d\r\n ",mtspeed4.Rotate_Speed,mtspeed4.Total_Time_M1,mtspeed4.Total_Time_M2);
					mtspeed4.Total_Time_M1 = 0;
					mtspeed4.Total_Time_M2 = 0;
				}
				mtspeed4.startcount = 0;
				HAL_TIM_IC_Start_IT(&htim3,TIM_CHANNEL_2);
			}
		}
		/* 减速器机械测速 */
		if(osEventFlagsGet (MT_EventHandle)&MT_EVENTBIT_5){
			osEventFlagsClear (MT_EventHandle, MT_EVENTBIT_5);
			if (mtspeed5.Endup_Flag != 0)                         //轮速信号捕获完成
			{
				if(mtspeed5.Total_Time_M1 == 0){
					mtspeed5.Rotate_Speed = 0;
					mtspeed5.Total_Time_M2 = 0;
					mtspeed5.Endup_Flag = 0;
				}
				else{
					mtspeed5.Endup_Flag = 0;
					if(time3_over2 == 0){
						mtspeed5.Rotate_Speed = (((5000.0*60*mtspeed5.Total_Time_M1)/(J_TOOTH_NUM*mtspeed5.Total_Time_M2)) * 2 * PI * WHEEL_RADIUS /GEAR_RATIO)*3.0/50;    //计算速度(km/h)
						printf(" SPEED5 = %d,M1 = %d,M2 =  %d\r\n",mtspeed5.Rotate_Speed,mtspeed5.Total_Time_M1,mtspeed5.Total_Time_M2);
					}
					else{
						time3_over2 = 0;
						mtspeed5.memory_value = 0;
					}
					sdtyrespeed[4][sdnum[4]++] = mtspeed5.Rotate_Speed;
					if(sdnum[4]>=10){
						sdnum[4] = 0;
						if(osEventFlagsGet (SD_EventHandle)&SD_EVENTBIT_3){
							res_flash = f_open(&SDFile, "0:/FWT_dat/tyrespeed/reducerspeed.txt",FA_OPEN_APPEND | FA_WRITE);
							if ( res_flash == FR_OK ){
//								printf("FWT_dat/tyrespeed/tyrespeed4.txt open success!");
								memset(sd_tyre, 0, sizeof(sd_tyre));
								if(RTC_Start_flag == 1){
									sprintf(sd_tyre,"\r\n%04d/%02d/%02d %02d:%02d:%02d",GetData.Year+2000,GetData.Month,GetData.Date,rtcTime.Hours,rtcTime.Minutes,rtcTime.Seconds);
								}else{
									sprintf(sd_tyre,"time interval : %dms\r\n",uwTick-uwtin[7]);
								}
								uwtin[7] = uwTick;
								f_write(&SDFile,sd_tyre,sizeof(sd_tyre),&moderator_bw);
								memset(sd_tyre, 0, sizeof(sd_tyre));
								sprintf(sd_tyre,"\r\nmoderator = %d km/h , %d km/h , %d km/h , %d km/h , %d km/h",sdtyrespeed[4][0],sdtyrespeed[4][1],sdtyrespeed[4][2],sdtyrespeed[4][3],sdtyrespeed[4][4]);
								f_write(&SDFile,sd_tyre,sizeof(sd_tyre),&moderator_bw);
								memset(sd_tyre, 0, sizeof(sd_tyre));
								sprintf(sd_tyre,"\r\nmoderator = %d km/h , %d km/h , %d km/h , %d km/h , %d km/h",sdtyrespeed[4][5],sdtyrespeed[4][6],sdtyrespeed[4][7],sdtyrespeed[4][8],sdtyrespeed[4][9]);
								f_write(&SDFile,sd_tyre,sizeof(sd_tyre),&moderator_bw);
							}
							else
							{
								printf("FWT_dat/tyrespeed/tyrespeed4.txt open fail!(%d)",res_flash);
							}
							f_close(&SDFile);
						}
					}
//					printf(" SPEED4 = %d,M1 = %d,M2 =  %d\r\n ",mtspeed4.Rotate_Speed,mtspeed4.Total_Time_M1,mtspeed4.Total_Time_M2);
					mtspeed5.Total_Time_M1 = 0;
					mtspeed5.Total_Time_M2 = 0;
				}
				mtspeed5.startcount = 0;
				HAL_TIM_IC_Start_IT(&htim3,TIM_CHANNEL_1);
			}
		}
		//左前
		tyre_msg[0] = (mtspeed1.Rotate_Speed >> 8);
		tyre_msg[1] = mtspeed1.Rotate_Speed &0xff;
		//左后
		tyre_msg[2] = (mtspeed3.Rotate_Speed >> 8);
		tyre_msg[3] = mtspeed3.Rotate_Speed &0xff;
		//右前
		tyre_msg[4] = (mtspeed4.Rotate_Speed >> 8);
		tyre_msg[5] = mtspeed4.Rotate_Speed &0xff;
		//右后
		tyre_msg[6] = (mtspeed2.Rotate_Speed >> 8);
		tyre_msg[7] = mtspeed2.Rotate_Speed &0xff;
		osEventFlagsSet (Can_EventHandle,CAN_EVENTBIT_2);
		if(dtu_device1.Onenet_Off_flag == 0&&dtu_device1.st_flag == 0){
//			printf("EVENTBIT_10\r\n");
			OneNet_Send(tyrespeed,TYRE_Device_ID,sizeof(tyrespeed));
		}
		osDelay(Type_Dat_Handle_Delay);
	}
  /* USER CODE END TyreSpeed_Handle */
}

void SD_Init_Handle(void *argument)
{
  /* USER CODE BEGIN SD_Init_Handle */
  /* Infinite loop */
  for(;;)
  {
		FRESULT res_flash;
		//挂载文件系统
		res_flash = f_mount(&SDFatFS,"0:",1);
		if(res_flash!=FR_OK)
		{
			printf("！！mount error！！(%d)\r\n",res_flash);
			osEventFlagsClear (SD_EventHandle,SD_EVENTBIT_1|SD_EVENTBIT_2|SD_EVENTBIT_3|SD_EVENTBIT_4);
		}
		else
		{
			printf("mount sucess！！\r\n");
			printf_sdcard_info();
			osEventFlagsSet (SD_EventHandle,SD_EVENTBIT_1|SD_EVENTBIT_2|SD_EVENTBIT_3|SD_EVENTBIT_4);
		}
    vTaskDelete(SD_Init_taskHandle);
  }
  /* USER CODE END SD_Init_Handle */
}

void RTC_Handle(void *argument)
{
  /* USER CODE BEGIN RTC_Handle */
  /* Infinite loop */
  for(;;)
  {
		if(RTC_Start_flag == 1)
		{
			HAL_RTC_GetTime(&hrtc,&rtcTime,RTC_FORMAT_BIN);
			HAL_RTC_GetDate(&hrtc,&GetData,RTC_FORMAT_BIN);
		}
//		printf("      %04d-%02d-%02d\r\n",GetData.Year+2000,GetData.Month,GetData.Date);
//		printf("      %02d-%02d-%02d\r\n",rtcTime.Hours,rtcTime.Minutes,rtcTime.Seconds);
    osDelay(RTC_Delay);
  }
  /* USER CODE END RTC_Handle */
}

void Canrx_Handle(void *argument)
{
  for(;;)
  {
    osDelay(1);
  }
}

/* USER CODE BEGIN Application */

/**********************************************************************
  * @ 函数名  ： HAL_CAN_RxFifo0MsgPendingCallback()
  * @ 功能说明： CAN数据接受回调函数
  * @ 参数    ： CAN_HandleTypeDef *hcan
  * @ 返回值  ： 无
  ********************************************************************/
void HAL_CAN_RxFifo0MsgPendingCallback(CAN_HandleTypeDef *hcan)
{
	if(hcan->Instance == CAN1)
	{
		HAL_CAN_GetRxMessage(&hcan1,CAN_RX_FIFO0,&RxMessage,canrx_dat);
		switch(RxMessage.StdId)
		{
			case(CLK_StdId2):{
				if((RxMessage.IDE==CAN_ID_STD) && (RxMessage.DLC==1)){
					UpdateTime_flag = canrx_dat[0];
				}
				break;
			}
			case(Wit_dat):{
				if((RxMessage.IDE==CAN_ID_STD) && (RxMessage.DLC==8)){
					WitCanDataIn(canrx_dat, RxMessage.DLC);
					osEventFlagsSet (Vcu_Event1Handle, EVENTBIT_0);
				}
				break;
			}
			default:
				break;
		}
		osSemaphoreRelease(CanBinarySemHandle);
	}
}
/**********************************************************************
  * @ 函数名  ： OneNet_Send()
	* @ 功能说明： 4g_DTU的数据发送函数
  * @ 参数    ： uint8_t *Send_date,uint8_t device_id,uint8_t dat_len
  * @ 返回值  ： 无
  ********************************************************************/
static void OneNet_Send(uint8_t *Send_date,uint8_t device_id,uint8_t dat_len)
{
	uint8_t Sdat[3] = {3,0,0x46};
	int res = 0;
	uint8_t j = 0;
//	osEventFlagsSet(Vcu_Event1Handle, EVENTBIT_3);
//	printf("%d",osEventFlagsGet (Vcu_Event1Handle)&EVENTBIT_3);
	if((osEventFlagsGet(Vcu_Event1Handle)&EVENTBIT_3) == 0){   //判断是否处于控制阶段 0处于配置状态 1处于透传状态
		osMutexAcquire(MqttMutexHandle,osWaitForever);
		dtu_device1.st_flag = 1;
		while(j<5){
					/*DTU进入透传状态*/
			 res = dtu_enter_transfermode();
			 if( res != 0 ){
				 j++;
					printf("DTU enter transparent mode failed !\r\n");
				 osDelay(10);
			 }
			 else{
				 osEventFlagsSet(Vcu_Event1Handle, EVENTBIT_3);	//			 dtu_device1.Dtumode_Switch_flag = 1;
				 printf("DTU enter transparent mode !\r\n");
				 OneNet_FillBuf(Send_date,device_id);
				 HAL_UART_Transmit(&huart2,&Sdat[0],sizeof(Sdat[0]),0xff);
				 HAL_UART_Transmit(&huart2,&Sdat[1],sizeof(Sdat[1]),0xff);
				 HAL_UART_Transmit(&huart2,&Sdat[2],sizeof(Sdat[2]),0xff);
				 HAL_UART_Transmit(&huart2,Send_date,dat_len,0xff);
				 break;
			 }
		}
		dtu_device1.st_flag = 0;
		j = 0;
		osMutexRelease(MqttMutexHandle);
	}
	else{
			osMutexAcquire(MqttMutexHandle,osWaitForever);
			OneNet_FillBuf(Send_date,device_id);
			HAL_UART_Transmit(&huart2,Send_date,dat_len,0xff);
			osMutexRelease(MqttMutexHandle);
	 }
}

/**********************************************************************
  * @ 函数名  ： OneNet_FillBuf
  * @ 功能说明： 封装数据
  * @ 参数    ： uint8_t *buff,uint8_t devicer_id
  * @ 返回值  ： 无
  ********************************************************************/
static void OneNet_FillBuf(uint8_t *buff,uint8_t devicer_id)
{
	osKernelLock ();
	switch(devicer_id)
	{
		case(Wit_Device_ID):{
			memset(buff, 0, sizeof(buff));
			sprintf((char *)buff, "{'WIT_ACC_AYRO_ANGLE':'\n%.3f,%.3f,%.3f\n%.3f,%.3f,%.3f\n%.3f,%.3f,%.3f\n'}"\
									,wit_dat1.fAcc[0], wit_dat1.fAcc[1], wit_dat1.fAcc[2]\
			            ,wit_dat1.fGyro[0], wit_dat1.fGyro[1], wit_dat1.fGyro[2]\
			            ,wit_dat1.fAngle[0], wit_dat1.fAngle[1], wit_dat1.fAngle[2]); //WIT_ACC_AYRO_ANGLE是数据流的一个名称，wit_dat1是数据值;
			break;
		}
		case(TYRE_Device_ID):{
			memset(buff, 0, sizeof(buff));
			sprintf((char *)buff, "{'Tyre_speed':'%d,%d,%d,%d'}",mtspeed1.Rotate_Speed,mtspeed2.Rotate_Speed,mtspeed3.Rotate_Speed,mtspeed4.Rotate_Speed);
			break;
		}
		case(XJ_Device_ID):{
			memset(buff, 0, sizeof(buff));
			sprintf((char *)buff, "{'XJWY_Dat':'%d,%d,%d,%d,%d'}",Wy_dat.displacement_dat,Wy_dat.xjwy1_dat,Wy_dat.xjwy2_dat,Wy_dat.xjwy3_dat,Wy_dat.xjwy4_dat);
			break;
		}
		case(GPS_Device_ID):{
			memset(buff, 0, sizeof(buff));
			sprintf((char *)buff, "{'Speed_dat':'%.1fm'}",(float)(gpsx.speed/=1000));
			break;
		}
		case(DTU_Device_ID):{
			memset(buff, 0, sizeof(buff));
			sprintf((char *)buff, "{'4G_signal':'%d'}",dtu_device1.Network_size);
			break;
		}
		default:break;
	}
	osKernelUnlock ();
}

/**********************************************************************
  * @ 函数名  ： HAL_UART_RxCpltCallback()
  * @ 功能说明： 用于处理接受gps模块数据
  * @ 参数    ： UART_HandleTypeDef *huart
  * @ 返回值  ： 无
  ********************************************************************/

void HAL_UART_RxCpltCallback(UART_HandleTypeDef *huart)
{
	if(huart->Instance == USART3){
		if((USART3_RX_STA&(1<<15))==0)//接收完的一批数据,还没有被处理,则不再接收其他数据
		{
			if(USART3_RX_STA<USART3_MAX_RECV_LEN)	//还可以接收数据
			{
				__HAL_TIM_SetCounter(&htim7,0);
				if(USART3_RX_STA==0)
				{
					__HAL_TIM_ENABLE(&htim7);
				}
				USART3_RX_BUF[USART3_RX_STA++]=usart_rx_char;	//记录接收到的值
			}else
			{
				USART3_RX_STA|=1<<15;				//强制标记接收完成
			}
		}
		HAL_UART_Receive_IT(&huart3,&usart_rx_char,1);
	}
}

/**********************************************************************
  * @ 函数名  ： Gps_Msg_Show()
  * @ 功能说明： 显示GPS定位信息
  * @ 参数    ： 无
  * @ 返回值  ： 无
  ********************************************************************/
static void Gps_Msg_Show(void)
{
// 	float tp;
	uint8_t Speed_date[64] = {0};
	static uint8_t Sd_gps_num = 0;
	char sd_gpsspeed[200] = {0};
	float sd_gpsspeeddat[10] = {0};
	FRESULT res_flash;
	UINT gps_bw;
//	tp=gpsx.longitude;
////	printf("Longitude:%.5f %1c\r\n",tp/=100000,gpsx.ewhemi);//得到经度字符串
//	tp=gpsx.latitude;
////	printf("Latitude:%.5f %1c \r\n",tp/=100000,gpsx.nshemi);//得到纬度字符串
//	tp=gpsx.altitude;
////	printf("Altitude:%.1fm \r\n",tp/=10);//得到高度字符串
//	speedfloat_tx.value = gpsx.speed/1000;
	speedfloat_tx.value = mtspeed5.Rotate_Speed;
//	printf("Speed:%.3fkm/h \r\n",speedfloat_tx.value);//得到速度字符串
	sd_gpsspeeddat[Sd_gps_num] = speedfloat_tx.value;
//	if(gpsx.fixmode<=3)														//定位状态
//	{
//		printf("Fix Mode:%s\r\n",fixmode_tbl[gpsx.fixmode]);
//	}
//	printf("Valid satellite:%02d\r\n",gpsx.posslnum);//用于定位的卫星数
//	printf("Visible satellite:%02d\r\n",gpsx.svnum%100);//可见卫星数
//	printf("UTC Date:%04d/%02d/%02d   \r\n",gpsx.utc.year,gpsx.utc.month,gpsx.utc.date); 					//显示UTC日期
//	printf("UTC Time:%02d:%02d:%02d   \r\n",gpsx.utc.hour,gpsx.utc.min,gpsx.utc.sec);							//显示UTC时间
	if(UpdateTime_flag != 1&&gpsx.utc.year > 2023){
		if(gpsx.utc.hour > 0&&gpsx.utc.min > 0&&gpsx.utc.sec > 0){
			Clkvalue[0] = gpsx.utc.year - 2000;
			Clkvalue[1] = gpsx.utc.month;
			Clkvalue[2] = gpsx.utc.date;
			Clkvalue[3] = gpsx.utc.hour + 8;
			Clkvalue[4] = gpsx.utc.min;
			Clkvalue[5] = gpsx.utc.sec;
			osEventFlagsSet(Can_EventHandle, CAN_EVENTBIT_5);
			RTC_TimeTypeDef sTime = {0};
			RTC_DateTypeDef sDate = {0};
			sTime.Hours = Clkvalue[3];
			sTime.Minutes = Clkvalue[4];
			sTime.Seconds = Clkvalue[5];
			sTime.DayLightSaving = RTC_DAYLIGHTSAVING_NONE;
			sTime.StoreOperation = RTC_STOREOPERATION_RESET;
			if (HAL_RTC_SetTime(&hrtc, &sTime, RTC_FORMAT_BCD) != HAL_OK)
			{
				Error_Handler();
			}
			sDate.WeekDay = RTC_WEEKDAY_SATURDAY;
			if(Clkvalue[1] < 10){
				sDate.Month = Clkvalue[1];
			}else{
				sDate.Month = 0x10|(Clkvalue[1]-10);
			}
			sDate.Date = Clkvalue[2];
			sDate.Year = Clkvalue[0];
			if (HAL_RTC_SetDate(&hrtc, &sDate, RTC_FORMAT_BCD) != HAL_OK)
			{
				Error_Handler();
			}
			osDelay(20);
			RTC_Start_flag = 1;
		}
	}
 osEventFlagsSet(Can_EventHandle, CAN_EVENTBIT_4);
	if(dtu_device1.Onenet_Off_flag == 0&&dtu_device1.st_flag == 0){
		OneNet_Send(Speed_date,GPS_Device_ID,sizeof(Speed_date));
	}
	if(Sd_gps_num++>=10){
		Sd_gps_num = 0;
		if(osEventFlagsGet (SD_EventHandle)&SD_EVENTBIT_4){
			res_flash = f_open(&SDFile, "0:/FWT_dat/gpsspeed.txt",FA_OPEN_APPEND | FA_WRITE);
			if ( res_flash == FR_OK ){
				memset(sd_gpsspeed, 0, sizeof(sd_gpsspeed));
				if(RTC_Start_flag == 1){
					sprintf(sd_gpsspeed,"\r\n%04d/%02d/%02d %02d:%02d:%02d",GetData.Year+2000,GetData.Month,GetData.Date,rtcTime.Hours,rtcTime.Minutes,rtcTime.Seconds);
				}else{
					sprintf(sd_gpsspeed,"time interval : %dms\r\n",uwTick-uwtin[1]);
				}
				uwtin[1] = uwTick;
				f_write(&SDFile,sd_gpsspeed,sizeof(sd_gpsspeed),&gps_bw);
				memset(sd_gpsspeed, 0, sizeof(sd_gpsspeed));
				sprintf(sd_gpsspeed,"\r\ngps_speed = %.3f km/h , %.3f km/h , %.3f km/h , %.3f km/h , %.3f km/h\r\ngps_speed = %.3f km/h , %.3f km/h , %.3f km/h , %.3f km/h , %.3f km/h"\
							,sd_gpsspeeddat[0],sd_gpsspeeddat[1],sd_gpsspeeddat[2],sd_gpsspeeddat[3],sd_gpsspeeddat[4],sd_gpsspeeddat[5],sd_gpsspeeddat[6],sd_gpsspeeddat[7],sd_gpsspeeddat[8]\
							,sd_gpsspeeddat[9]);
				f_write(&SDFile,sd_gpsspeed,sizeof(sd_gpsspeed),&gps_bw);
			}
			else
			{
				printf("FWT_dat/tyrespeed/tyrespeed4.txt open fail!(%d)",res_flash);
			}
			f_close(&SDFile);
		}
	}
}

/**********************************************************************
  * @ 函数名  ： HAL_TIM_IC_CaptureCallback()
  * @ 功能说明： 定时器输入捕获中断返回处理
  * @ 参数    ： TIM_HandleTypeDef *htim
  * @ 返回值  ： 无
  ********************************************************************/
void HAL_TIM_IC_CaptureCallback(TIM_HandleTypeDef *htim)
{
	static uint32_t Pulse_Count1 = 1,Pulse_Count2 = 1,Pulse_Count3 = 1,Pulse_Count4 = 1,Pulse_Count5 = 1;
	if(htim->Instance == TIM2)
	{
		if(mtspeed1.Startup_Flag == 1){
			Pulse_Count1++;
		}
		if(mtspeed2.Startup_Flag == 1){
			Pulse_Count2++;
		}
		//左前
		if(HAL_GPIO_ReadPin(GPIOA,GPIO_PIN_1) == 1)
		{
			mtspeed1.speed_zero = 0;
			if(mtspeed1.Endup_Flag != 0){                                                       //采样周期结束捕获第二次上升沿
//				printf("Capture2\r\n");
				HAL_TIM_IC_Stop_IT(htim,TIM_CHANNEL_2);																					 //禁止捕获通道1中断
				mtspeed1.Total_Time_M1 = Pulse_Count1;                                 					 //获取采样周期内的M1
				mtspeed1.Total_Time_M2 = __HAL_TIM_GetCounter(htim) - 	mtspeed1.memory_value;		 //获取高频时钟周期M2
				Pulse_Count1 = 1;                                                                //脉冲置1
				mtspeed1.Startup_Flag = 0;                                                       //首次标志清零
				osEventFlagsSet (MT_EventHandle, MT_EVENTBIT_1);
			}else{
//				printf("Capture1\r\n");
				if(mtspeed1.startcount == 0){
					mtspeed1.startcount = 1;
					mtspeed1.Startup_Flag = 1;							                                //标记首次捕获上升沿
				  mtspeed1.memory_value = __HAL_TIM_GetCounter(&htim2);
				  mtspeed1.timecountflag = 1;
				}
			}
		}
		//右后
		if(HAL_GPIO_ReadPin(GPIOA,GPIO_PIN_5) == 1)
		{
			mtspeed2.speed_zero = 0;
			if(mtspeed2.Endup_Flag != 0){                                                       //采样周期结束捕获第二次上升沿
//				printf("tim2_channel_Capture1\r\n");
				HAL_TIM_IC_Stop_IT(htim,TIM_CHANNEL_1);																					 //禁止捕获通道1中断
				mtspeed2.Total_Time_M1 = Pulse_Count2;                                 					 //获取采样周期内的M1
				mtspeed2.Total_Time_M2 = __HAL_TIM_GetCounter(htim) - 	mtspeed2.memory_value;		 //获取高频时钟周期M2
				Pulse_Count2 = 1;                                                                //脉冲置1
				mtspeed2.Startup_Flag = 0;                                                       //首次标志清零                                                    //实际采样结束标志
				osEventFlagsSet (MT_EventHandle, MT_EVENTBIT_2);
			}else{
//				printf("tim2_channel_Capture2\r\n");
				if(mtspeed2.startcount == 0){
					mtspeed2.startcount = 1;
					mtspeed2.Startup_Flag = 1;							                                //标记首次捕获上升沿
				  mtspeed2.memory_value = __HAL_TIM_GetCounter(&htim2);
				  mtspeed2.timecountflag = 1;
				}				                             					                            //标记首次捕获上升沿
			}
		}
	}
	if(htim->Instance == TIM5)
	{
		if(mtspeed3.Startup_Flag == 1){
			Pulse_Count3++;
		}
		//右前
		if(HAL_GPIO_ReadPin(GPIOA,GPIO_PIN_0) == 1)
		{
			mtspeed3.speed_zero = 0;
			if(mtspeed3.Endup_Flag != 0){                                                       //采样周期结束捕获第二次上升沿
				HAL_TIM_IC_Stop_IT(&htim5,TIM_CHANNEL_1);																					 //禁止捕获通道1中断
				mtspeed3.Total_Time_M1 = Pulse_Count3;                                 					 //获取采样周期内的M1
				mtspeed3.Total_Time_M2 = __HAL_TIM_GetCounter(&htim5) - 	mtspeed3.memory_value;		 //获取高频时钟周期M2
				Pulse_Count3 = 1;                                                                //脉冲置1
				mtspeed3.Startup_Flag = 0;                                                       //首次标志清零                                                    //实际采样结束标志
				osEventFlagsSet (MT_EventHandle, MT_EVENTBIT_3);
			}else{
				if(mtspeed3.startcount == 0){
					mtspeed3.startcount = 1;
					mtspeed3.Startup_Flag = 1;							                                //标记首次捕获上升沿
				  mtspeed3.memory_value = __HAL_TIM_GetCounter(&htim5);
				  mtspeed3.timecountflag = 1;
				}				                             					                            //标记首次捕获上升沿
			}
		}
	}
	if(htim->Instance == TIM3)
	{
		if(mtspeed4.Startup_Flag == 1){
			Pulse_Count4++;
		}
		if(mtspeed5.Startup_Flag == 1){
			Pulse_Count5++;
		}
		//左后
		if(HAL_GPIO_ReadPin(GPIOA,GPIO_PIN_7) == 1)
		{
			mtspeed4.speed_zero = 0;
			if(mtspeed4.Endup_Flag != 0){                                                       //采样周期结束捕获第二次上升沿
//				printf("tim3_channel_Capture1\r\n");
				HAL_TIM_IC_Stop_IT(&htim3,TIM_CHANNEL_2);																					 //禁止捕获通道1中断
				mtspeed4.Total_Time_M1 = Pulse_Count4;                                 					 //获取采样周期内的M1
				mtspeed4.Total_Time_M2 = __HAL_TIM_GetCounter(&htim3) - mtspeed4.memory_value;		 											//获取高频时钟周期M2
				Pulse_Count4 = 1;                                                                //脉冲置1
				mtspeed4.Startup_Flag = 0;                                                       //首次标志清零                                                     //实际采样结束标志
				osEventFlagsSet (MT_EventHandle, MT_EVENTBIT_4);
			}else{
//				printf("tim3_channel_Capture2\r\n");
				if(mtspeed4.startcount == 0){
					mtspeed4.startcount = 1;
					mtspeed4.Startup_Flag = 1;							                                //标记首次捕获上升沿
					mtspeed4.memory_value = __HAL_TIM_GetCounter(&htim3);
				  mtspeed4.timecountflag = 1;
				}				                             					                            //标记首次捕获上升沿
			}
		}
		//减速器
		if(HAL_GPIO_ReadPin(GPIOA,GPIO_PIN_6) == 1)
		{
			mtspeed5.speed_zero = 0;
			if(mtspeed5.Endup_Flag != 0){                                                       //采样周期结束捕获第二次上升沿
				HAL_TIM_IC_Stop_IT(&htim3,TIM_CHANNEL_1);																					//禁止捕获通道1中断
				mtspeed5.Total_Time_M1 = Pulse_Count5;                                 					  //获取采样周期内的M1
				mtspeed5.Total_Time_M2 = __HAL_TIM_GetCounter(&htim3) - mtspeed5.memory_value;	  //获取高频时钟周期M2
				Pulse_Count5 = 1;                                                                 //脉冲置1
				mtspeed5.Startup_Flag = 0;                                                        //首次标志清零                                                     //实际采样结束标志
				osEventFlagsSet (MT_EventHandle, MT_EVENTBIT_5);
			}else{
				if(mtspeed5.startcount == 0){
					mtspeed5.startcount = 1;
					mtspeed5.Startup_Flag = 1;							                                //标记首次捕获上升沿
					mtspeed5.memory_value = __HAL_TIM_GetCounter(&htim3);
				  mtspeed5.timecountflag = 1;
				}				                             					                            //标记首次捕获上升沿
			}
		}
	}
}

/**********************************************************************
  * @ 函数名  ： printf_sdcard_info()
  * @ 功能说明： 读取SD卡基本信息
  * @ 参数    ： 无
  * @ 返回值  ： 无
  ********************************************************************/
inline static void printf_sdcard_info(void)
{
	uint64_t CardCap;      	//SD卡容量
	HAL_SD_CardCIDTypeDef SDCard_CID;

	HAL_SD_GetCardCID(&hsd,&SDCard_CID);	//获取CID
	HAL_SD_GetCardInfo(&hsd,&SDCardInfo);                    //获取SD卡信息
	CardCap=(uint64_t)(SDCardInfo.LogBlockNbr)*(uint64_t)(SDCardInfo.LogBlockSize);	//计算SD卡容量
	switch(SDCardInfo.CardType)
	{
		case CARD_SDSC:
		{
			if(SDCardInfo.CardVersion == CARD_V1_X)
				printf("Card Type:SDSC V1\r\n");
			else if(SDCardInfo.CardVersion == CARD_V2_X)
				printf("Card Type:SDSC V2\r\n");
		}
		break;
		case CARD_SDHC_SDXC:printf("Card Type:SDHC\r\n");break;
		default:break;
	}
  printf("Card ManufacturerID: %d \r\n",SDCard_CID.ManufacturerID);				//制造商ID
 	printf("CardVersion:         %d \r\n",(uint32_t)(SDCardInfo.CardVersion));		//卡版本号
	printf("Class:               %d \r\n",(uint32_t)(SDCardInfo.Class));		    //
 	printf("Card RCA(RelCardAdd):%d \r\n",SDCardInfo.RelCardAdd);					//卡相对地址
	printf("Card BlockNbr:       %d \r\n",SDCardInfo.BlockNbr);						//块数量
 	printf("Card BlockSize:      %d \r\n",SDCardInfo.BlockSize);					//块大小
	printf("LogBlockNbr:         %d \r\n",(uint32_t)(SDCardInfo.LogBlockNbr));		//逻辑块数量
	printf("LogBlockSize:        %d \r\n",(uint32_t)(SDCardInfo.LogBlockSize));		//逻辑块大小
	printf("Card Capacity:       %d MB\r\n",(uint32_t)(CardCap>>20));				//卡容量
}

void Bsp_Start_IT(void)
{
	HAL_ADC_Start_IT(&hadc1);
	HAL_ADC_Start_DMA(&hadc2,adc2_value,sizeof(adc2_value)/4);

	__HAL_UART_CLEAR_IDLEFLAG(&huart2);
  __HAL_UART_ENABLE_IT(&huart2,UART_IT_IDLE);
	HAL_UART_Receive_DMA(&huart2,rx_4g_buffer,sizeof(rx_4g_buffer));

	HAL_TIM_IC_Start_IT(&htim2,TIM_CHANNEL_1);
	HAL_TIM_IC_Start_IT(&htim2,TIM_CHANNEL_2);
	__HAL_TIM_ENABLE(&htim2);

	HAL_TIM_IC_Start_IT(&htim3,TIM_CHANNEL_1);
	HAL_TIM_IC_Start_IT(&htim3,TIM_CHANNEL_2);
	__HAL_TIM_ENABLE(&htim3);

	HAL_TIM_IC_Start_IT(&htim5,TIM_CHANNEL_1);
	__HAL_TIM_ENABLE(&htim5);

	HAL_TIM_Base_Start_IT(&htim7);
	HAL_TIM_Base_Start_IT(&htim13);
	HAL_TIM_Base_Start_IT(&htim14);

	HAL_CAN_ActivateNotification(&hcan1,CAN_IT_RX_FIFO0_MSG_PENDING);
  HAL_CAN_Start(&hcan1);
}

/* USER CODE END Application */
